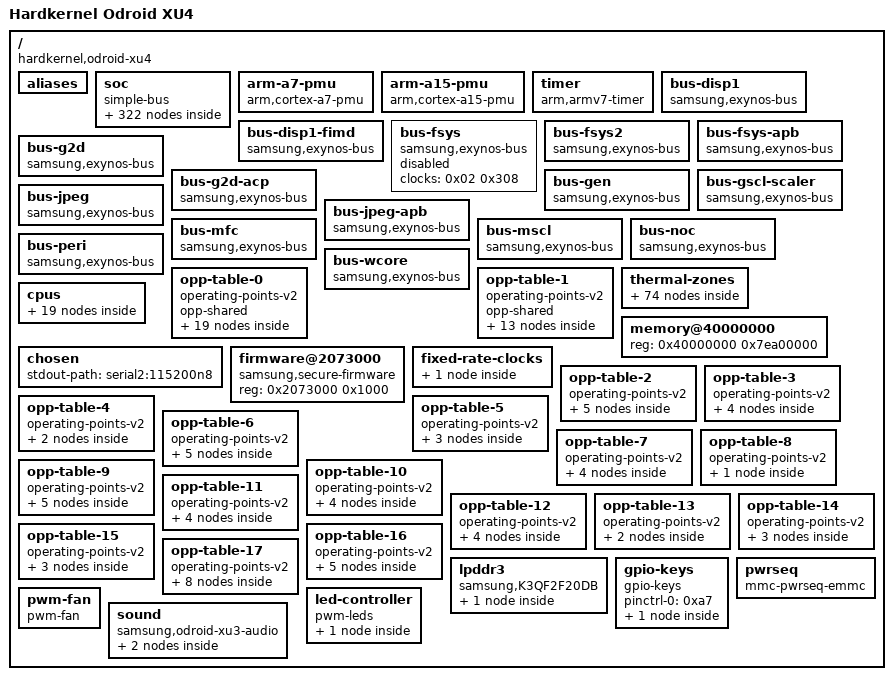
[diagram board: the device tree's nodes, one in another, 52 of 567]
/*
 * Copyright Linux Kernel Team
 *
 * SPDX-License-Identifier: GPL-2.0-only
 *
 * This file is derived from an intermediate build stage of the
 * Linux kernel. The licenses of all input files to this process
 * are compatible with GPL-2.0-only.
 */

/dts-v1/;

/ {
	interrupt-parent = <0x01>;
	#address-cells = <0x01>;
	#size-cells = <0x01>;
	compatible = "hardkernel,odroid-xu4", "samsung,exynos5800", "samsung,exynos5";
	model = "Hardkernel Odroid XU4";

	aliases {
		i2c0 = "/soc/i2c@12c60000";
		i2c1 = "/soc/i2c@12c70000";
		i2c2 = "/soc/i2c@12c80000";
		i2c3 = "/soc/i2c@12c90000";
		serial0 = "/soc/serial@12c00000";
		serial1 = "/soc/serial@12c10000";
		serial2 = "/soc/serial@12c20000";
		serial3 = "/soc/serial@12c30000";
		i2c4 = "/soc/i2c@12ca0000";
		i2c5 = "/soc/i2c@12cb0000";
		i2c6 = "/soc/i2c@12cc0000";
		i2c7 = "/soc/i2c@12cd0000";
		usbdrdphy0 = "/soc/phy@12100000";
		usbdrdphy1 = "/soc/phy@12500000";
		pinctrl0 = "/soc/pinctrl@13400000";
		pinctrl1 = "/soc/pinctrl@13410000";
		pinctrl2 = "/soc/pinctrl@14000000";
		pinctrl3 = "/soc/pinctrl@14010000";
		pinctrl4 = "/soc/pinctrl@3860000";
		i2c8 = "/soc/i2c@12e00000";
		i2c9 = "/soc/i2c@12e10000";
		i2c10 = "/soc/i2c@12e20000";
		gsc0 = "/soc/video-scaler@13e00000";
		gsc1 = "/soc/video-scaler@13e10000";
		spi0 = "/soc/spi@12d20000";
		spi1 = "/soc/spi@12d30000";
		spi2 = "/soc/spi@12d40000";
		mmc2 = "/soc/mmc@12220000";
		mmc0 = "/soc/mmc@12200000";
	};

	soc {
		compatible = "simple-bus";
		#address-cells = <0x01>;
		#size-cells = <0x01>;
		ranges;

		chipid@10000000 {
			compatible = "samsung,exynos4210-chipid";
			reg = <0x10000000 0x100>;
		};

		memory-controller@12250000 {
			compatible = "samsung,exynos4210-srom";
			reg = <0x12250000 0x14>;
		};

		interrupt-controller@10440000 {
			compatible = "samsung,exynos4210-combiner";
			#interrupt-cells = <0x02>;
			interrupt-controller;
			samsung,combiner-nr = <0x20>;
			reg = <0x10440000 0x1000>;
			interrupts = <0x00 0x00 0x04 0x00 0x01 0x04 0x00 0x02 0x04 0x00 0x03 0x04 0x00 0x04 0x04 0x00 0x05 0x04 0x00 0x06 0x04 0x00 0x07 0x04 0x00 0x08 0x04 0x00 0x09 0x04 0x00 0x0a 0x04 0x00 0x0b 0x04 0x00 0x0c 0x04 0x00 0x0d 0x04 0x00 0x0e 0x04 0x00 0x0f 0x04 0x00 0x10 0x04 0x00 0x11 0x04 0x00 0x12 0x04 0x00 0x13 0x04 0x00 0x14 0x04 0x00 0x15 0x04 0x00 0x16 0x04 0x00 0x17 0x04 0x00 0x18 0x04 0x00 0x19 0x04 0x00 0x1a 0x04 0x00 0x1b 0x04 0x00 0x1c 0x04 0x00 0x1d 0x04 0x00 0x1e 0x04 0x00 0x1f 0x04>;
			phandle = <0x0e>;
		};

		interrupt-controller@10481000 {
			compatible = "arm,gic-400", "arm,cortex-a15-gic";
			#interrupt-cells = <0x03>;
			interrupt-controller;
			reg = <0x10481000 0x1000 0x10482000 0x2000 0x10484000 0x2000 0x10486000 0x2000>;
			interrupts = <0x01 0x09 0xf04>;
			phandle = <0x01>;
		};

		syscon@10050000 {
			compatible = "samsung,exynos5-sysreg", "syscon";
			reg = <0x10050000 0x5000>;
			phandle = <0x05>;
		};

		serial@12c00000 {
			compatible = "samsung,exynos4210-uart";
			reg = <0x12c00000 0x100>;
			interrupts = <0x00 0x33 0x04>;
			clocks = <0x02 0x101 0x02 0x80>;
			clock-names = "uart", "clk_uart_baud0";
			dmas = <0x03 0x0d 0x03 0x0e>;
			dma-names = "rx", "tx";
		};

		serial@12c10000 {
			compatible = "samsung,exynos4210-uart";
			reg = <0x12c10000 0x100>;
			interrupts = <0x00 0x34 0x04>;
			clocks = <0x02 0x102 0x02 0x81>;
			clock-names = "uart", "clk_uart_baud0";
			dmas = <0x04 0x0f 0x04 0x10>;
			dma-names = "rx", "tx";
		};

		serial@12c20000 {
			compatible = "samsung,exynos4210-uart";
			reg = <0x12c20000 0x100>;
			interrupts = <0x00 0x35 0x04>;
			clocks = <0x02 0x103 0x02 0x82>;
			clock-names = "uart", "clk_uart_baud0";
			dmas = <0x03 0x0f 0x03 0x10>;
			dma-names = "rx", "tx";
		};

		serial@12c30000 {
			compatible = "samsung,exynos4210-uart";
			reg = <0x12c30000 0x100>;
			interrupts = <0x00 0x36 0x04>;
			clocks = <0x02 0x104 0x02 0x83>;
			clock-names = "uart", "clk_uart_baud0";
			dmas = <0x04 0x11 0x04 0x12>;
			dma-names = "rx", "tx";
		};

		i2c@12c60000 {
			compatible = "samsung,s3c2440-i2c";
			reg = <0x12c60000 0x100>;
			interrupts = <0x00 0x38 0x04>;
			#address-cells = <0x01>;
			#size-cells = <0x00>;
			samsung,sysreg-phandle = <0x05>;
			status = "disabled";
			clocks = <0x02 0x105>;
			clock-names = "i2c";
			pinctrl-names = "default";
			pinctrl-0 = <0x06>;
		};

		i2c@12c70000 {
			compatible = "samsung,s3c2440-i2c";
			reg = <0x12c70000 0x100>;
			interrupts = <0x00 0x39 0x04>;
			#address-cells = <0x01>;
			#size-cells = <0x00>;
			samsung,sysreg-phandle = <0x05>;
			status = "disabled";
			clocks = <0x02 0x106>;
			clock-names = "i2c";
			pinctrl-names = "default";
			pinctrl-0 = <0x07>;
		};

		i2c@12c80000 {
			compatible = "samsung,s3c2440-i2c";
			reg = <0x12c80000 0x100>;
			interrupts = <0x00 0x3a 0x04>;
			#address-cells = <0x01>;
			#size-cells = <0x00>;
			samsung,sysreg-phandle = <0x05>;
			status = "okay";
			clocks = <0x02 0x107>;
			clock-names = "i2c";
			pinctrl-names = "default";
			pinctrl-0 = <0x08>;
			samsung,i2c-sda-delay = <0x64>;
			samsung,i2c-max-bus-freq = <0x101d0>;
			phandle = <0x4e>;
		};

		i2c@12c90000 {
			compatible = "samsung,s3c2440-i2c";
			reg = <0x12c90000 0x100>;
			interrupts = <0x00 0x3b 0x04>;
			#address-cells = <0x01>;
			#size-cells = <0x00>;
			samsung,sysreg-phandle = <0x05>;
			status = "disabled";
			clocks = <0x02 0x108>;
			clock-names = "i2c";
			pinctrl-names = "default";
			pinctrl-0 = <0x09>;
		};

		pwm@12dd0000 {
			compatible = "samsung,exynos4210-pwm";
			reg = <0x12dd0000 0x100>;
			interrupts = <0x00 0x24 0x04 0x00 0x25 0x04 0x00 0x26 0x04 0x00 0x27 0x04 0x00 0x28 0x04>;
			samsung,pwm-outputs = <0x00 0x02>;
			#pwm-cells = <0x03>;
			clocks = <0x02 0x117>;
			clock-names = "timers";
			pinctrl-0 = <0x0a 0x0b>;
			pinctrl-names = "default";
			status = "okay";
			phandle = <0xaa>;
		};

		rtc@101e0000 {
			compatible = "samsung,s3c6410-rtc";
			reg = <0x101e0000 0x100>;
			interrupts = <0x00 0x2b 0x04 0x00 0x2c 0x04>;
			status = "okay";
			clocks = <0x02 0x13d 0x0c 0x00>;
			clock-names = "rtc", "rtc_src";
			interrupt-parent = <0x0d>;
		};

		fimd@14400000 {
			compatible = "samsung,exynos5420-fimd";
			interrupt-parent = <0x0e>;
			reg = <0x14400000 0x40000>;
			interrupt-names = "fifo", "vsync", "lcd_sys";
			interrupts = <0x12 0x04 0x12 0x05 0x12 0x06>;
			samsung,sysreg = <0x05>;
			status = "disabled";
			clocks = <0x02 0x93 0x02 0x1a5>;
			clock-names = "sclk_fimd", "fimd";
			power-domains = <0x0f>;
			iommus = <0x10 0x11>;
			iommu-names = "m0", "m1";
		};

		dp-controller@145b0000 {
			compatible = "samsung,exynos5-dp";
			reg = <0x145b0000 0x1000>;
			interrupts = <0x0a 0x03>;
			interrupt-parent = <0x0e>;
			status = "disabled";
			clocks = <0x02 0x19c>;
			clock-names = "dp";
			phys = <0x12>;
			phy-names = "dp";
			power-domains = <0x0f>;
		};

		sss@10830000 {
			compatible = "samsung,exynos4210-secss";
			reg = <0x10830000 0x300>;
			interrupts = <0x00 0x70 0x04>;
			clocks = <0x02 0x1d7>;
			clock-names = "secss";
		};

		rng@10830400 {
			compatible = "samsung,exynos5250-prng";
			reg = <0x10830400 0x200>;
			clocks = <0x02 0x1d7>;
			clock-names = "secss";
		};

		rng@10830600 {
			compatible = "samsung,exynos5250-trng";
			reg = <0x10830600 0x100>;
			clocks = <0x02 0x1d7>;
			clock-names = "secss";
		};

		g2d@10850000 {
			compatible = "samsung,exynos5250-g2d";
			reg = <0x10850000 0x1000>;
			interrupts = <0x00 0x5b 0x04>;
			status = "okay";
			iommus = <0x13 0x14>;
			clocks = <0x02 0x1e1>;
			clock-names = "fimg2d";
		};

		sram@2020000 {
			compatible = "mmio-sram";
			reg = <0x2020000 0x54000>;
			#address-cells = <0x01>;
			#size-cells = <0x01>;
			ranges = <0x00 0x2020000 0x54000>;

			smp-sram@0 {
				compatible = "samsung,exynos4210-sysram";
				reg = <0x00 0x1000>;
			};

			smp-sram@53000 {
				compatible = "samsung,exynos4210-sysram-ns";
				reg = <0x53000 0x1000>;
			};
		};

		timer@101c0000 {
			compatible = "samsung,exynos5420-mct", "samsung,exynos4210-mct";
			reg = <0x101c0000 0xb00>;
			interrupts-extended = <0x0e 0x17 0x03 0x0e 0x17 0x04 0x0e 0x19 0x02 0x0e 0x19 0x03 0x01 0x00 0x78 0x04 0x01 0x00 0x79 0x04 0x01 0x00 0x7a 0x04 0x01 0x00 0x7b 0x04 0x01 0x00 0x80 0x04 0x01 0x00 0x81 0x04 0x01 0x00 0x82 0x04 0x01 0x00 0x83 0x04>;
			clocks = <0x02 0x01 0x02 0x13b>;
			clock-names = "fin_pll", "mct";
		};

		watchdog@101d0000 {
			compatible = "samsung,exynos5420-wdt";
			reg = <0x101d0000 0x100>;
			interrupts = <0x00 0x2a 0x04>;
			clocks = <0x02 0x13c>;
			clock-names = "watchdog";
			samsung,syscon-phandle = <0x0d>;
		};

		adc@12d10000 {
			compatible = "samsung,exynos-adc-v2";
			reg = <0x12d10000 0x100>;
			interrupts = <0x00 0x6a 0x04>;
			#io-channel-cells = <0x01>;
			status = "okay";
			clocks = <0x02 0x10e>;
			clock-names = "adc";
			samsung,syscon-phandle = <0x0d>;
			vdd-supply = <0x15>;
		};

		i2c@12ca0000 {
			compatible = "samsung,exynos5250-hsi2c";
			reg = <0x12ca0000 0x1000>;
			interrupts = <0x00 0x3c 0x04>;
			#address-cells = <0x01>;
			#size-cells = <0x00>;
			status = "okay";
			clocks = <0x02 0x109>;
			clock-names = "hsi2c";
			pinctrl-names = "default";
			pinctrl-0 = <0x16>;

			pmic@66 {
				compatible = "samsung,s2mps11-pmic";
				reg = <0x66>;
				samsung,s2mps11-acokb-ground;
				interrupt-parent = <0x17>;
				interrupts = <0x04 0x08>;
				pinctrl-names = "default";
				pinctrl-0 = <0x18>;
				wakeup-source;

				clocks {
					compatible = "samsung,s2mps11-clk";
					#clock-cells = <0x01>;
					clock-output-names = "s2mps11_ap", "s2mps11_cp", "s2mps11_bt";
					phandle = <0x0c>;
				};

				regulators {

					LDO1 {
						regulator-name = "vdd_ldo1";
						regulator-min-microvolt = <0xf4240>;
						regulator-max-microvolt = <0xf4240>;
						regulator-always-on;
					};

					LDO2 {
						regulator-name = "vdd_ldo2";
						regulator-min-microvolt = <0x1b7740>;
						regulator-max-microvolt = <0x1b7740>;
						regulator-always-on;
					};

					LDO3 {
						regulator-name = "vddq_mmc0";
						regulator-min-microvolt = <0x1b7740>;
						regulator-max-microvolt = <0x1b7740>;
						phandle = <0x30>;
					};

					LDO4 {
						regulator-name = "vdd_adc";
						regulator-min-microvolt = <0x1b7740>;
						regulator-max-microvolt = <0x1b7740>;
						phandle = <0x15>;

						regulator-state-mem {
							regulator-off-in-suspend;
						};
					};

					LDO5 {
						regulator-name = "vdd_ldo5";
						regulator-min-microvolt = <0x1b7740>;
						regulator-max-microvolt = <0x1b7740>;
						regulator-always-on;

						regulator-state-mem {
							regulator-off-in-suspend;
						};
					};

					LDO6 {
						regulator-name = "vdd_ldo6";
						regulator-min-microvolt = <0xf4240>;
						regulator-max-microvolt = <0xf4240>;
						regulator-always-on;
						phandle = <0x52>;

						regulator-state-mem {
							regulator-off-in-suspend;
						};
					};

					LDO7 {
						regulator-name = "vdd_ldo7";
						regulator-min-microvolt = <0x1b7740>;
						regulator-max-microvolt = <0x1b7740>;
						regulator-always-on;
						phandle = <0x51>;

						regulator-state-mem {
							regulator-off-in-suspend;
						};
					};

					LDO8 {
						regulator-name = "vdd_ldo8";
						regulator-min-microvolt = <0x1b7740>;
						regulator-max-microvolt = <0x1b7740>;
						regulator-always-on;

						regulator-state-mem {
							regulator-off-in-suspend;
						};
					};

					LDO9 {
						regulator-name = "vdd_ldo9";
						regulator-min-microvolt = <0x2dc6c0>;
						regulator-max-microvolt = <0x2dc6c0>;
						regulator-always-on;
						phandle = <0x1e>;

						regulator-state-mem {
							regulator-off-in-suspend;
						};
					};

					LDO10 {
						regulator-name = "vdd_ldo10";
						regulator-min-microvolt = <0x1b7740>;
						regulator-max-microvolt = <0x1b7740>;
						regulator-always-on;

						regulator-state-mem {
							regulator-off-in-suspend;
						};
					};

					LDO11 {
						regulator-name = "vdd_ldo11";
						regulator-min-microvolt = <0xf4240>;
						regulator-max-microvolt = <0xf4240>;
						regulator-always-on;
						phandle = <0x1f>;

						regulator-state-mem {
							regulator-off-in-suspend;
						};
					};

					LDO12 {
						regulator-name = "vdd_ldo12";
						regulator-min-microvolt = "", "\f5";
						regulator-max-microvolt = <0x243d58>;
					};

					LDO13 {
						regulator-name = "vddq_mmc2";
						regulator-min-microvolt = <0x1b7740>;
						regulator-max-microvolt = <0x2ab980>;
						phandle = <0x38>;

						regulator-state-mem {
							regulator-off-in-suspend;
						};
					};

					LDO14 {
						regulator-name = "vdd_ldo14";
						regulator-min-microvolt = "", "\f5";
						regulator-max-microvolt = <0x3c45b0>;
					};

					LDO15 {
						regulator-name = "vdd_ldo15";
						regulator-min-microvolt = <0x325aa0>;
						regulator-max-microvolt = <0x325aa0>;
						regulator-always-on;

						regulator-state-mem {
							regulator-off-in-suspend;
						};
					};

					LDO16 {
						regulator-name = "vdd_ldo16";
						regulator-min-microvolt = "", "\f5";
						regulator-max-microvolt = <0x3c45b0>;
					};

					LDO17 {
						regulator-name = "vdd_ldo17";
						regulator-min-microvolt = <0x325aa0>;
						regulator-max-microvolt = <0x325aa0>;
						regulator-always-on;

						regulator-state-mem {
							regulator-off-in-suspend;
						};
					};

					LDO18 {
						regulator-name = "vdd_emmc_1V8";
						regulator-min-microvolt = <0x1b7740>;
						regulator-max-microvolt = <0x1b7740>;
						phandle = <0x2f>;

						regulator-state-mem {
							regulator-off-in-suspend;
						};
					};

					LDO19 {
						regulator-name = "vdd_sd";
						regulator-min-microvolt = <0x2ab980>;
						regulator-max-microvolt = <0x2ab980>;
						phandle = <0x37>;

						regulator-state-mem {
							regulator-off-in-suspend;
						};
					};

					LDO20 {
						regulator-name = "vdd_ldo20";
						regulator-min-microvolt = "", "\f5";
						regulator-max-microvolt = <0x3c45b0>;
					};

					LDO21 {
						regulator-name = "vdd_ldo21";
						regulator-min-microvolt = "", "\f5";
						regulator-max-microvolt = <0x3c45b0>;
					};

					LDO22 {
						regulator-name = "vdd_ldo22";
						regulator-min-microvolt = "", "\f5";
						regulator-max-microvolt = <0x243d58>;
					};

					LDO23 {
						regulator-name = "vdd_mifs";
						regulator-min-microvolt = <0x10c8e0>;
						regulator-max-microvolt = <0x10c8e0>;
						regulator-always-on;

						regulator-state-mem {
							regulator-off-in-suspend;
						};
					};

					LDO24 {
						regulator-name = "vdd_ldo24";
						regulator-min-microvolt = "", "\f5";
						regulator-max-microvolt = <0x3c45b0>;
					};

					LDO25 {
						regulator-name = "vdd_ldo25";
						regulator-min-microvolt = "", "\f5";
						regulator-max-microvolt = <0x3c45b0>;
					};

					LDO26 {
						regulator-name = "vdd_ldo26";
						regulator-min-microvolt = <0x2dc6c0>;
						regulator-max-microvolt = <0x2dc6c0>;
						regulator-always-on;

						regulator-state-mem {
							regulator-off-in-suspend;
						};
					};

					LDO27 {
						regulator-name = "vdd_g3ds";
						regulator-min-microvolt = <0xf4240>;
						regulator-max-microvolt = <0xf4240>;
						regulator-always-on;

						regulator-state-mem {
							regulator-off-in-suspend;
						};
					};

					LDO28 {
						regulator-name = "vdd_ldo28";
						regulator-min-microvolt = "", "\f5";
						regulator-max-microvolt = <0x3c45b0>;

						regulator-state-mem {
							regulator-off-in-suspend;
						};
					};

					LDO29 {
						regulator-name = "vdd_ldo29";
						regulator-min-microvolt = "", "\f5";
						regulator-max-microvolt = <0x3c45b0>;
					};

					LDO30 {
						regulator-name = "vdd_ldo30";
						regulator-min-microvolt = "", "\f5";
						regulator-max-microvolt = <0x3c45b0>;
					};

					LDO31 {
						regulator-name = "vdd_ldo31";
						regulator-min-microvolt = "", "\f5";
						regulator-max-microvolt = <0x3c45b0>;
					};

					LDO32 {
						regulator-name = "vdd_ldo32";
						regulator-min-microvolt = "", "\f5";
						regulator-max-microvolt = <0x3c45b0>;
					};

					LDO33 {
						regulator-name = "vdd_ldo33";
						regulator-min-microvolt = "", "\f5";
						regulator-max-microvolt = <0x3c45b0>;
					};

					LDO34 {
						regulator-name = "vdd_ldo34";
						regulator-min-microvolt = "", "\f5";
						regulator-max-microvolt = <0x3c45b0>;
					};

					LDO35 {
						regulator-name = "vdd_ldo35";
						regulator-min-microvolt = "", "\f5";
						regulator-max-microvolt = <0x243d58>;
					};

					LDO36 {
						regulator-name = "vdd_ldo36";
						regulator-min-microvolt = "", "\f5";
						regulator-max-microvolt = <0x3c45b0>;
					};

					LDO37 {
						regulator-name = "vdd_ldo37";
						regulator-min-microvolt = "", "\f5";
						regulator-max-microvolt = <0x3c45b0>;
					};

					LDO38 {
						regulator-name = "vdd_ldo38";
						regulator-min-microvolt = "", "\f5";
						regulator-max-microvolt = <0x3c45b0>;
					};

					BUCK1 {
						regulator-name = "vdd_mif";
						regulator-min-microvolt = "", "\f5";
						regulator-max-microvolt = <0x13d620>;
						regulator-always-on;
						regulator-boot-on;
						phandle = <0x3f>;

						regulator-state-mem {
							regulator-off-in-suspend;
						};
					};

					BUCK2 {
						regulator-name = "vdd_arm";
						regulator-min-microvolt = "", "\f5";
						regulator-max-microvolt = <0x16e360>;
						regulator-always-on;
						regulator-boot-on;
						regulator-coupled-with = <0x19>;
						regulator-coupled-max-spread = <0x493e0>;
						phandle = <0x1a>;

						regulator-state-mem {
							regulator-off-in-suspend;
						};
					};

					BUCK3 {
						regulator-name = "vdd_int";
						regulator-min-microvolt = "", "\f5";
						regulator-max-microvolt = <0x155cc0>;
						regulator-always-on;
						regulator-boot-on;
						regulator-coupled-with = <0x1a>;
						regulator-coupled-max-spread = <0x493e0>;
						phandle = <0x19>;

						regulator-state-mem {
							regulator-off-in-suspend;
						};
					};

					BUCK4 {
						regulator-name = "vdd_g3d";
						regulator-min-microvolt = "", "\f5";
						regulator-max-microvolt = <0x155cc0>;
						regulator-boot-on;
						regulator-always-on;
						phandle = <0x5c>;

						regulator-state-mem {
							regulator-off-in-suspend;
						};
					};

					BUCK5 {
						regulator-name = "vdd_mem";
						regulator-min-microvolt = "", "\f5";
						regulator-max-microvolt = <0x155cc0>;
						regulator-always-on;
						regulator-boot-on;
					};

					BUCK6 {
						regulator-name = "vdd_kfc";
						regulator-min-microvolt = "", "\f5";
						regulator-max-microvolt = <0x16e360>;
						regulator-always-on;
						regulator-boot-on;
						phandle = <0xa4>;

						regulator-state-mem {
							regulator-off-in-suspend;
						};
					};

					BUCK7 {
						regulator-name = "vdd_1.35v_ldo";
						regulator-min-microvolt = <0x124f80>;
						regulator-max-microvolt = <0x16e360>;
						regulator-always-on;
						regulator-boot-on;
					};

					BUCK8 {
						regulator-name = "vdd_2.0v_ldo";
						regulator-min-microvolt = <0x1b7740>;
						regulator-max-microvolt = <0x200b20>;
						regulator-always-on;
						regulator-boot-on;
					};

					BUCK9 {
						regulator-name = "vdd_2.8v_ldo";
						regulator-min-microvolt = <0x2dc6c0>;
						regulator-max-microvolt = <0x393870>;
						regulator-always-on;
						regulator-boot-on;

						regulator-state-mem {
							regulator-off-in-suspend;
						};
					};

					BUCK10 {
						regulator-name = "vdd_vmem";
						regulator-min-microvolt = <0x2b7cd0>;
						regulator-max-microvolt = <0x2b7cd0>;
						regulator-always-on;
						regulator-boot-on;

						regulator-state-mem {
							regulator-off-in-suspend;
						};
					};
				};
			};
		};

		i2c@12cb0000 {
			compatible = "samsung,exynos5250-hsi2c";
			reg = <0x12cb0000 0x1000>;
			interrupts = <0x00 0x3d 0x04>;
			#address-cells = <0x01>;
			#size-cells = <0x00>;
			status = "disabled";
			clocks = <0x02 0x10a>;
			clock-names = "hsi2c";
			pinctrl-names = "default";
			pinctrl-0 = <0x1b>;
		};

		i2c@12cc0000 {
			compatible = "samsung,exynos5250-hsi2c";
			reg = <0x12cc0000 0x1000>;
			interrupts = <0x00 0x3e 0x04>;
			#address-cells = <0x01>;
			#size-cells = <0x00>;
			status = "disabled";
			clocks = <0x02 0x10b>;
			clock-names = "hsi2c";
			pinctrl-names = "default";
			pinctrl-0 = <0x1c>;
		};

		i2c@12cd0000 {
			compatible = "samsung,exynos5250-hsi2c";
			reg = <0x12cd0000 0x1000>;
			interrupts = <0x00 0x3f 0x04>;
			#address-cells = <0x01>;
			#size-cells = <0x00>;
			status = "disabled";
			clocks = <0x02 0x10c>;
			clock-names = "hsi2c";
			pinctrl-names = "default";
			pinctrl-0 = <0x1d>;
		};

		usb@12000000 {
			compatible = "samsung,exynos5250-dwusb3";
			#address-cells = <0x01>;
			#size-cells = <0x01>;
			ranges = <0x00 0x12000000 0x10000>;
			clocks = <0x02 0x16e>;
			clock-names = "usbdrd30";
			vdd33-supply = <0x1e>;
			vdd10-supply = <0x1f>;

			usb@0 {
				compatible = "snps,dwc3";
				reg = <0x00 0x10000>;
				interrupts = <0x00 0x48 0x04>;
				phys = <0x20 0x00 0x20 0x01>;
				phy-names = "usb2-phy", "usb3-phy";
				snps,dis_u3_susphy_quirk;
				dr_mode = "host";
			};
		};

		phy@12100000 {
			compatible = "samsung,exynos5420-usbdrd-phy";
			reg = <0x12100000 0x100>;
			#phy-cells = <0x01>;
			clocks = <0x02 0x16e 0x02 0x98>;
			clock-names = "phy", "ref";
			samsung,pmu-syscon = <0x0d>;
			phandle = <0x20>;
		};

		usb@12400000 {
			compatible = "samsung,exynos5250-dwusb3";
			#address-cells = <0x01>;
			#size-cells = <0x01>;
			ranges = <0x00 0x12400000 0x10000>;
			clocks = <0x02 0x16f>;
			clock-names = "usbdrd30";
			vdd33-supply = <0x1e>;
			vdd10-supply = <0x1f>;

			usb@0 {
				compatible = "snps,dwc3";
				reg = <0x00 0x10000>;
				phys = <0x21 0x00 0x21 0x01>;
				phy-names = "usb2-phy", "usb3-phy";
				snps,dis_u3_susphy_quirk;
				interrupts = <0x00 0x49 0x04>;
				dr_mode = "host";
			};
		};

		phy@12500000 {
			compatible = "samsung,exynos5420-usbdrd-phy";
			reg = <0x12500000 0x100>;
			#phy-cells = <0x01>;
			clocks = <0x02 0x16f 0x02 0x99>;
			clock-names = "phy", "ref";
			samsung,pmu-syscon = <0x0d>;
			phandle = <0x21>;
		};

		usb@12110000 {
			compatible = "samsung,exynos4210-ehci";
			reg = <0x12110000 0x100>;
			interrupts = <0x00 0x47 0x04>;
			phys = <0x22 0x00>;
			phy-names = "host";
			clocks = <0x02 0x16d>;
			clock-names = "usbhost";
		};

		usb@12120000 {
			compatible = "samsung,exynos4210-ohci";
			reg = <0x12120000 0x100>;
			interrupts = <0x00 0x47 0x04>;
			phys = <0x22 0x00>;
			phy-names = "host";
			clocks = <0x02 0x16d>;
			clock-names = "usbhost";
		};

		phy@12130000 {
			compatible = "samsung,exynos5420-usb2-phy";
			reg = <0x12130000 0x100>;
			#phy-cells = <0x01>;
			clocks = <0x02 0x16d 0x02 0x98>;
			clock-names = "phy", "ref";
			samsung,sysreg-phandle = <0x05>;
			samsung,pmureg-phandle = <0x0d>;
			phandle = <0x22>;
		};

		cci@10d20000 {
			compatible = "arm,cci-400";
			#address-cells = <0x01>;
			#size-cells = <0x01>;
			reg = <0x10d20000 0x1000>;
			ranges = <0x00 0x10d20000 0x6000>;

			slave-if@4000 {
				compatible = "arm,cci-400-ctrl-if";
				interface-type = "ace";
				reg = <0x4000 0x1000>;
				phandle = <0xa2>;
			};

			slave-if@5000 {
				compatible = "arm,cci-400-ctrl-if";
				interface-type = "ace";
				reg = <0x5000 0x1000>;
				phandle = <0xa5>;
			};
		};

		clock-controller@10010000 {
			compatible = "samsung,exynos5800-clock", "syscon";
			reg = <0x10010000 0x30000>;
			#clock-cells = <0x01>;
			phandle = <0x02>;
		};

		audss-clock-controller@3810000 {
			compatible = "samsung,exynos5420-audss-clock";
			reg = <0x3810000 0x0c>;
			#clock-cells = <0x01>;
			clocks = <0x02 0x01 0x02 0x9f 0x02 0x94 0x02 0x95>;
			clock-names = "pll_ref", "pll_in", "sclk_audio", "sclk_pcm_in";
			power-domains = <0x23>;
			phandle = <0x40>;
		};

		codec@11000000 {
			compatible = "samsung,mfc-v8";
			reg = <0x11000000 0x10000>;
			interrupts = <0x00 0x60 0x04>;
			clocks = <0x02 0x191>;
			clock-names = "mfc";
			power-domains = <0x24>;
			iommus = <0x25 0x26>;
			iommu-names = "left", "right";
		};

		mmc@12200000 {
			compatible = "samsung,exynos5420-dw-mshc-smu";
			interrupts = <0x00 0x4b 0x04>;
			#address-cells = <0x01>;
			#size-cells = <0x00>;
			reg = <0x12200000 0x2000>;
			clocks = <0x02 0x15f 0x02 0x84>;
			clock-names = "biu", "ciu";
			fifo-depth = <0x40>;
			status = "okay";
			mmc-pwrseq = <0x27>;
			card-detect-delay = <0xc8>;
			samsung,dw-mshc-ciu-div = <0x03>;
			samsung,dw-mshc-sdr-timing = <0x00 0x04>;
			samsung,dw-mshc-ddr-timing = <0x00 0x02>;
			samsung,dw-mshc-hs400-timing = <0x00 0x02>;
			samsung,read-strobe-delay = <0x5a>;
			pinctrl-names = "default";
			pinctrl-0 = <0x28 0x29 0x2a 0x2b 0x2c 0x2d 0x2e>;
			bus-width = <0x08>;
			cap-mmc-highspeed;
			mmc-ddr-1_8v;
			mmc-hs200-1_8v;
			mmc-hs400-1_8v;
			max-frequency = <0xbebc200>;
			vmmc-supply = <0x2f>;
			vqmmc-supply = <0x30>;
		};

		mmc@12210000 {
			compatible = "samsung,exynos5420-dw-mshc-smu";
			interrupts = <0x00 0x4c 0x04>;
			#address-cells = <0x01>;
			#size-cells = <0x00>;
			reg = <0x12210000 0x2000>;
			clocks = <0x02 0x160 0x02 0x85>;
			clock-names = "biu", "ciu";
			fifo-depth = <0x40>;
			status = "disabled";
		};

		mmc@12220000 {
			compatible = "samsung,exynos5420-dw-mshc";
			interrupts = <0x00 0x4d 0x04>;
			#address-cells = <0x01>;
			#size-cells = <0x00>;
			reg = <0x12220000 0x1000>;
			clocks = <0x02 0x161 0x02 0x86>;
			clock-names = "biu", "ciu";
			fifo-depth = <0x40>;
			status = "okay";
			card-detect-delay = <0xc8>;
			samsung,dw-mshc-ciu-div = <0x03>;
			samsung,dw-mshc-sdr-timing = <0x00 0x04>;
			samsung,dw-mshc-ddr-timing = <0x00 0x02>;
			pinctrl-names = "default";
			pinctrl-0 = <0x31 0x32 0x33 0x34 0x35 0x36>;
			bus-width = <0x04>;
			cap-sd-highspeed;
			max-frequency = <0xbebc200>;
			vmmc-supply = <0x37>;
			vqmmc-supply = <0x38>;
			sd-uhs-sdr50;
			sd-uhs-sdr104;
			sd-uhs-ddr50;
		};

		memory-controller@10c20000 {
			compatible = "samsung,exynos5422-dmc";
			reg = <0x10c20000 0x10000 0x10c30000 0x10000>;
			clocks = <0x02 0x08 0x02 0x294 0x02 0x31d 0x02 0x0b 0x02 0x28f 0x02 0xa2 0x02 0x290 0x02 0x28e>;
			clock-names = "fout_spll", "mout_sclk_spll", "ff_dout_spll2", "fout_bpll", "mout_bpll", "sclk_bpll", "mout_mx_mspll_ccore", "mout_mclk_cdrex";
			samsung,syscon-clk = <0x02>;
			status = "okay";
			devfreq-events = <0x39 0x3a 0x3b 0x3c>;
			device-handle = <0x3d>;
			operating-points-v2 = <0x3e>;
			vdd-supply = <0x3f>;
		};

		nocp@10ca1000 {
			compatible = "samsung,exynos5420-nocp";
			reg = <0x10ca1000 0x200>;
			status = "okay";
			phandle = <0x7e>;
		};

		nocp@10ca1400 {
			compatible = "samsung,exynos5420-nocp";
			reg = <0x10ca1400 0x200>;
			status = "okay";
			phandle = <0x7f>;
		};

		nocp@10ca1800 {
			compatible = "samsung,exynos5420-nocp";
			reg = <0x10ca1800 0x200>;
			status = "okay";
			phandle = <0x80>;
		};

		nocp@10ca1c00 {
			compatible = "samsung,exynos5420-nocp";
			reg = <0x10ca1c00 0x200>;
			status = "okay";
			phandle = <0x81>;
		};

		nocp@11a51000 {
			compatible = "samsung,exynos5420-nocp";
			reg = <0x11a51000 0x200>;
			status = "disabled";
		};

		nocp@11a51400 {
			compatible = "samsung,exynos5420-nocp";
			reg = <0x11a51400 0x200>;
			status = "disabled";
		};

		ppmu@10d00000 {
			compatible = "samsung,exynos-ppmu";
			reg = <0x10d00000 0x2000>;
			clocks = <0x02 0x20f>;
			clock-names = "ppmu";
			status = "okay";

			events {

				ppmu-event3-dmc0-0 {
					event-name = "ppmu-event3-dmc0-0";
					phandle = <0x39>;
				};
			};
		};

		ppmu@10d10000 {
			compatible = "samsung,exynos-ppmu";
			reg = <0x10d10000 0x2000>;
			clocks = <0x02 0x210>;
			clock-names = "ppmu";
			status = "okay";

			events {

				ppmu-event3-dmc0-1 {
					event-name = "ppmu-event3-dmc0-1";
					phandle = <0x3a>;
				};
			};
		};

		ppmu@10d60000 {
			compatible = "samsung,exynos-ppmu";
			reg = <0x10d60000 0x2000>;
			clocks = <0x02 0x211>;
			clock-names = "ppmu";
			status = "okay";

			events {

				ppmu-event3-dmc1-0 {
					event-name = "ppmu-event3-dmc1-0";
					phandle = <0x3b>;
				};
			};
		};

		ppmu@10d70000 {
			compatible = "samsung,exynos-ppmu";
			reg = <0x10d70000 0x2000>;
			clocks = <0x02 0x212>;
			clock-names = "ppmu";
			status = "okay";

			events {

				ppmu-event3-dmc1-1 {
					event-name = "ppmu-event3-dmc1-1";
					phandle = <0x3c>;
				};
			};
		};

		power-domain@10044000 {
			compatible = "samsung,exynos4210-pd";
			reg = <0x10044000 0x20>;
			#power-domain-cells = <0x00>;
			label = "GSC";
			phandle = <0x57>;
		};

		power-domain@10044020 {
			compatible = "samsung,exynos4210-pd";
			reg = <0x10044020 0x20>;
			#power-domain-cells = <0x00>;
			label = "ISP";
		};

		power-domain@10044060 {
			compatible = "samsung,exynos4210-pd";
			reg = <0x10044060 0x20>;
			#power-domain-cells = <0x00>;
			label = "MFC";
			phandle = <0x24>;
		};

		power-domain@10044080 {
			compatible = "samsung,exynos4210-pd";
			reg = <0x10044080 0x20>;
			#power-domain-cells = <0x00>;
			label = "G3D";
			phandle = <0x5a>;
		};

		power-domain@100440c0 {
			compatible = "samsung,exynos4210-pd";
			reg = <0x100440c0 0x20>;
			#power-domain-cells = <0x00>;
			label = "DISP";
			phandle = <0x0f>;
		};

		power-domain@100440e0 {
			compatible = "samsung,exynos4210-pd";
			reg = <0x100440e0 0x20>;
			#power-domain-cells = <0x00>;
			label = "MAU";
			phandle = <0x23>;
		};

		power-domain@10044120 {
			compatible = "samsung,exynos4210-pd";
			reg = <0x10044120 0x20>;
			#power-domain-cells = <0x00>;
			label = "MSC";
			phandle = <0x5d>;
		};

		pinctrl@13400000 {
			compatible = "samsung,exynos5420-pinctrl";
			reg = <0x13400000 0x1000>;
			interrupts = <0x00 0x2d 0x04>;

			wakeup-interrupt-controller {
				compatible = "samsung,exynos4210-wakeup-eint";
				interrupt-parent = <0x01>;
				interrupts = <0x00 0x20 0x04>;
			};

			gpy7-gpio-bank {
				gpio-controller;
				#gpio-cells = <0x02>;
				interrupt-controller;
				#interrupt-cells = <0x02>;
			};

			gpx0-gpio-bank {
				gpio-controller;
				#gpio-cells = <0x02>;
				interrupt-controller;
				interrupt-parent = <0x0e>;
				#interrupt-cells = <0x02>;
				interrupts = <0x17 0x00 0x18 0x00 0x19 0x00 0x19 0x01 0x1a 0x00 0x1a 0x01 0x1b 0x00 0x1b 0x01>;
				phandle = <0x17>;
			};

			gpx1-gpio-bank {
				gpio-controller;
				#gpio-cells = <0x02>;
				interrupt-controller;
				interrupt-parent = <0x0e>;
				#interrupt-cells = <0x02>;
				interrupts = <0x1c 0x00 0x1c 0x01 0x1d 0x00 0x1d 0x01 0x1e 0x00 0x1e 0x01 0x1f 0x00 0x1f 0x01>;
			};

			gpx2-gpio-bank {
				gpio-controller;
				#gpio-cells = <0x02>;
				interrupt-controller;
				#interrupt-cells = <0x02>;
			};

			gpx3-gpio-bank {
				gpio-controller;
				#gpio-cells = <0x02>;
				interrupt-controller;
				#interrupt-cells = <0x02>;
				phandle = <0x4f>;
			};

			dp-hpd-pins {
				samsung,pins = "gpx0-7";
				samsung,pin-function = <0x03>;
				samsung,pin-pud = <0x00>;
				samsung,pin-drv = <0x00>;
			};

			hdmi-cec-pins {
				samsung,pins = "gpx3-6";
				samsung,pin-function = <0x03>;
				samsung,pin-pud = <0x00>;
				samsung,pin-drv = <0x00>;
				phandle = <0x54>;
			};

			s2mps11-irq-pins {
				samsung,pins = "gpx0-4";
				samsung,pin-function = <0x0f>;
				samsung,pin-pud = <0x00>;
				samsung,pin-drv = <0x00>;
				phandle = <0x18>;
			};

			power-key-pins {
				samsung,pins = "gpx0-3";
				samsung,pin-function = <0x00>;
				samsung,pin-pud = <0x00>;
				samsung,pin-drv = <0x00>;
				phandle = <0xa7>;
			};

			hdmi-hpd-irq-pins {
				samsung,pins = "gpx3-7";
				samsung,pin-function = <0x00>;
				samsung,pin-pud = <0x01>;
				samsung,pin-drv = <0x00>;
				phandle = <0x50>;
			};
		};

		pinctrl@13410000 {
			compatible = "samsung,exynos5420-pinctrl";
			reg = <0x13410000 0x1000>;
			interrupts = <0x00 0x4e 0x04>;

			gpc0-gpio-bank {
				gpio-controller;
				#gpio-cells = <0x02>;
				interrupt-controller;
				#interrupt-cells = <0x02>;
			};

			gpc1-gpio-bank {
				gpio-controller;
				#gpio-cells = <0x02>;
				interrupt-controller;
				#interrupt-cells = <0x02>;
			};

			gpc2-gpio-bank {
				gpio-controller;
				#gpio-cells = <0x02>;
				interrupt-controller;
				#interrupt-cells = <0x02>;
			};

			gpc3-gpio-bank {
				gpio-controller;
				#gpio-cells = <0x02>;
				interrupt-controller;
				#interrupt-cells = <0x02>;
			};

			gpc4-gpio-bank {
				gpio-controller;
				#gpio-cells = <0x02>;
				interrupt-controller;
				#interrupt-cells = <0x02>;
			};

			gpd1-gpio-bank {
				gpio-controller;
				#gpio-cells = <0x02>;
				interrupt-controller;
				#interrupt-cells = <0x02>;
				phandle = <0xa9>;
			};

			gpy0-gpio-bank {
				gpio-controller;
				#gpio-cells = <0x02>;
			};

			gpy1-gpio-bank {
				gpio-controller;
				#gpio-cells = <0x02>;
			};

			gpy2-gpio-bank {
				gpio-controller;
				#gpio-cells = <0x02>;
			};

			gpy3-gpio-bank {
				gpio-controller;
				#gpio-cells = <0x02>;
			};

			gpy4-gpio-bank {
				gpio-controller;
				#gpio-cells = <0x02>;
			};

			gpy5-gpio-bank {
				gpio-controller;
				#gpio-cells = <0x02>;
			};

			gpy6-gpio-bank {
				gpio-controller;
				#gpio-cells = <0x02>;
			};

			sd0-clk-pins {
				samsung,pins = "gpc0-0";
				samsung,pin-function = <0x02>;
				samsung,pin-pud = <0x00>;
				samsung,pin-drv = <0x03>;
				phandle = <0x28>;
			};

			sd0-cmd-pins {
				samsung,pins = "gpc0-1";
				samsung,pin-function = <0x02>;
				samsung,pin-pud = <0x00>;
				samsung,pin-drv = <0x03>;
				phandle = <0x29>;
			};

			sd0-cd-pins {
				samsung,pins = "gpc0-2";
				samsung,pin-function = <0x02>;
				samsung,pin-pud = <0x03>;
				samsung,pin-drv = <0x03>;
				phandle = <0x2d>;
			};

			sd0-bus-width1-pins {
				samsung,pins = "gpc0-3";
				samsung,pin-function = <0x02>;
				samsung,pin-pud = <0x03>;
				samsung,pin-drv = <0x03>;
				phandle = <0x2a>;
			};

			sd0-bus-width4-pins {
				samsung,pins = "gpc0-4", "gpc0-5", "gpc0-6";
				samsung,pin-function = <0x02>;
				samsung,pin-pud = <0x03>;
				samsung,pin-drv = <0x03>;
				phandle = <0x2b>;
			};

			sd0-bus-width8-pins {
				samsung,pins = "gpc3-0", "gpc3-1", "gpc3-2", "gpc3-3";
				samsung,pin-function = <0x02>;
				samsung,pin-pud = <0x03>;
				samsung,pin-drv = <0x03>;
				phandle = <0x2c>;
			};

			sd0-rclk-pins {
				samsung,pins = "gpc0-7";
				samsung,pin-function = <0x02>;
				samsung,pin-pud = <0x01>;
				samsung,pin-drv = <0x03>;
				phandle = <0x2e>;
			};

			sd1-clk-pins {
				samsung,pins = "gpc1-0";
				samsung,pin-function = <0x02>;
				samsung,pin-pud = <0x00>;
				samsung,pin-drv = <0x03>;
			};

			sd1-cmd-pins {
				samsung,pins = "gpc1-1";
				samsung,pin-function = <0x02>;
				samsung,pin-pud = <0x00>;
				samsung,pin-drv = <0x03>;
			};

			sd1-cd-pins {
				samsung,pins = "gpc1-2";
				samsung,pin-function = <0x02>;
				samsung,pin-pud = <0x03>;
				samsung,pin-drv = <0x03>;
			};

			sd1-int-pins {
				samsung,pins = "gpd1-1";
				samsung,pin-function = <0x02>;
				samsung,pin-pud = <0x03>;
				samsung,pin-drv = <0x00>;
			};

			sd1-bus-width1-pins {
				samsung,pins = "gpc1-3";
				samsung,pin-function = <0x02>;
				samsung,pin-pud = <0x03>;
				samsung,pin-drv = <0x03>;
			};

			sd1-bus-width4-pins {
				samsung,pins = "gpc1-4", "gpc1-5", "gpc1-6";
				samsung,pin-function = <0x02>;
				samsung,pin-pud = <0x03>;
				samsung,pin-drv = <0x03>;
			};

			sd1-bus-width8-pins {
				samsung,pins = "gpd1-4", "gpd1-5", "gpd1-6", "gpd1-7";
				samsung,pin-function = <0x02>;
				samsung,pin-pud = <0x03>;
				samsung,pin-drv = <0x03>;
			};

			sd2-clk-pins {
				samsung,pins = "gpc2-0";
				samsung,pin-function = <0x02>;
				samsung,pin-pud = <0x00>;
				samsung,pin-drv = <0x03>;
				phandle = <0x31>;
			};

			sd2-cmd-pins {
				samsung,pins = "gpc2-1";
				samsung,pin-function = <0x02>;
				samsung,pin-pud = <0x00>;
				samsung,pin-drv = <0x03>;
				phandle = <0x32>;
			};

			sd2-cd-pins {
				samsung,pins = "gpc2-2";
				samsung,pin-function = <0x02>;
				samsung,pin-pud = <0x03>;
				samsung,pin-drv = <0x03>;
				phandle = <0x33>;
			};

			sd2-bus-width1-pins {
				samsung,pins = "gpc2-3";
				samsung,pin-function = <0x02>;
				samsung,pin-pud = <0x03>;
				samsung,pin-drv = <0x03>;
				phandle = <0x35>;
			};

			sd2-bus-width4-pins {
				samsung,pins = "gpc2-4", "gpc2-5", "gpc2-6";
				samsung,pin-function = <0x02>;
				samsung,pin-pud = <0x03>;
				samsung,pin-drv = <0x03>;
				phandle = <0x36>;
			};

			sd2-wp-pins {
				samsung,pins = "gpc4-0";
				samsung,pin-function = <0x02>;
				samsung,pin-pud = <0x01>;
				samsung,pin-drv = <0x03>;
				phandle = <0x34>;
			};

			emmc-nrst-pins {
				samsung,pins = "gpd1-0";
				samsung,pin-function = <0x00>;
				samsung,pin-pud = <0x00>;
				samsung,pin-drv = <0x00>;
				phandle = <0xa8>;
			};
		};

		pinctrl@14000000 {
			compatible = "samsung,exynos5420-pinctrl";
			reg = <0x14000000 0x1000>;
			interrupts = <0x00 0x2e 0x04>;

			gpe0-gpio-bank {
				gpio-controller;
				#gpio-cells = <0x02>;
				interrupt-controller;
				#interrupt-cells = <0x02>;
			};

			gpe1-gpio-bank {
				gpio-controller;
				#gpio-cells = <0x02>;
				interrupt-controller;
				#interrupt-cells = <0x02>;
			};

			gpf0-gpio-bank {
				gpio-controller;
				#gpio-cells = <0x02>;
				interrupt-controller;
				#interrupt-cells = <0x02>;
			};

			gpf1-gpio-bank {
				gpio-controller;
				#gpio-cells = <0x02>;
				interrupt-controller;
				#interrupt-cells = <0x02>;
			};

			gpg0-gpio-bank {
				gpio-controller;
				#gpio-cells = <0x02>;
				interrupt-controller;
				#interrupt-cells = <0x02>;
			};

			gpg1-gpio-bank {
				gpio-controller;
				#gpio-cells = <0x02>;
				interrupt-controller;
				#interrupt-cells = <0x02>;
			};

			gpg2-gpio-bank {
				gpio-controller;
				#gpio-cells = <0x02>;
				interrupt-controller;
				#interrupt-cells = <0x02>;
			};

			gpj4-gpio-bank {
				gpio-controller;
				#gpio-cells = <0x02>;
				interrupt-controller;
				#interrupt-cells = <0x02>;
			};

			cam-gpio-a-pins {
				samsung,pins = "gpe0-0", "gpe0-1", "gpe0-2", "gpe0-3", "gpe0-4", "gpe0-5", "gpe0-6", "gpe0-7", "gpe1-0", "gpe1-1";
				samsung,pin-function = <0x02>;
				samsung,pin-pud = <0x00>;
				samsung,pin-drv = <0x00>;
			};

			cam-gpio-b-pins {
				samsung,pins = "gpf0-0", "gpf0-1", "gpf0-2", "gpf0-3", "gpf1-0", "gpf1-1", "gpf1-2", "gpf1-3";
				samsung,pin-function = <0x03>;
				samsung,pin-pud = <0x00>;
				samsung,pin-drv = <0x00>;
			};

			cam-i2c2-bus-pins {
				samsung,pins = "gpf0-4", "gpf0-5";
				samsung,pin-function = <0x02>;
				samsung,pin-pud = <0x03>;
				samsung,pin-drv = <0x00>;
			};

			cam-spi1-bus-pins {
				samsung,pins = "gpe0-4", "gpe0-5", "gpf0-2", "gpf0-3";
				samsung,pin-function = <0x04>;
				samsung,pin-pud = <0x00>;
				samsung,pin-drv = <0x00>;
			};

			cam-i2c1-bus-pins {
				samsung,pins = "gpf0-2", "gpf0-3";
				samsung,pin-function = <0x02>;
				samsung,pin-pud = <0x03>;
				samsung,pin-drv = <0x00>;
			};

			cam-i2c0-bus-pins {
				samsung,pins = "gpf0-0", "gpf0-1";
				samsung,pin-function = <0x02>;
				samsung,pin-pud = <0x03>;
				samsung,pin-drv = <0x00>;
			};

			cam-spi0-bus-pins {
				samsung,pins = "gpf1-0", "gpf1-1", "gpf1-2", "gpf1-3";
				samsung,pin-function = <0x02>;
				samsung,pin-pud = <0x00>;
				samsung,pin-drv = <0x00>;
			};

			cam-bayrgb-bus-pins {
				samsung,pins = "gpg0-0", "gpg0-1", "gpg0-2", "gpg0-3", "gpg0-4", "gpg0-5", "gpg0-6", "gpg0-7", "gpg1-0", "gpg1-1", "gpg1-2", "gpg1-3", "gpg1-4", "gpg1-5", "gpg1-6", "gpg1-7", "gpg2-0";
				samsung,pin-function = <0x02>;
				samsung,pin-pud = <0x00>;
				samsung,pin-drv = <0x00>;
			};
		};

		pinctrl@14010000 {
			compatible = "samsung,exynos5420-pinctrl";
			reg = <0x14010000 0x1000>;
			interrupts = <0x00 0x32 0x04>;

			gpa0-gpio-bank {
				gpio-controller;
				#gpio-cells = <0x02>;
				interrupt-controller;
				#interrupt-cells = <0x02>;
			};

			gpa1-gpio-bank {
				gpio-controller;
				#gpio-cells = <0x02>;
				interrupt-controller;
				#interrupt-cells = <0x02>;
			};

			gpa2-gpio-bank {
				gpio-controller;
				#gpio-cells = <0x02>;
				interrupt-controller;
				#interrupt-cells = <0x02>;
			};

			gpb0-gpio-bank {
				gpio-controller;
				#gpio-cells = <0x02>;
				interrupt-controller;
				#interrupt-cells = <0x02>;
			};

			gpb1-gpio-bank {
				gpio-controller;
				#gpio-cells = <0x02>;
				interrupt-controller;
				#interrupt-cells = <0x02>;
			};

			gpb2-gpio-bank {
				gpio-controller;
				#gpio-cells = <0x02>;
				interrupt-controller;
				#interrupt-cells = <0x02>;
			};

			gpb3-gpio-bank {
				gpio-controller;
				#gpio-cells = <0x02>;
				interrupt-controller;
				#interrupt-cells = <0x02>;
			};

			gpb4-gpio-bank {
				gpio-controller;
				#gpio-cells = <0x02>;
				interrupt-controller;
				#interrupt-cells = <0x02>;
			};

			gph0-gpio-bank {
				gpio-controller;
				#gpio-cells = <0x02>;
				interrupt-controller;
				#interrupt-cells = <0x02>;
			};

			uart0-data-pins {
				samsung,pins = "gpa0-0", "gpa0-1";
				samsung,pin-function = <0x02>;
				samsung,pin-pud = <0x00>;
				samsung,pin-drv = <0x00>;
			};

			uart0-fctl-pins {
				samsung,pins = "gpa0-2", "gpa0-3";
				samsung,pin-function = <0x02>;
				samsung,pin-pud = <0x00>;
				samsung,pin-drv = <0x00>;
			};

			uart1-data-pins {
				samsung,pins = "gpa0-4", "gpa0-5";
				samsung,pin-function = <0x02>;
				samsung,pin-pud = <0x00>;
				samsung,pin-drv = <0x00>;
			};

			uart1-fctl-pins {
				samsung,pins = "gpa0-6", "gpa0-7";
				samsung,pin-function = <0x02>;
				samsung,pin-pud = <0x00>;
				samsung,pin-drv = <0x00>;
			};

			i2c2-bus-pins {
				samsung,pins = "gpa0-6", "gpa0-7";
				samsung,pin-function = <0x03>;
				samsung,pin-pud = <0x03>;
				samsung,pin-drv = <0x00>;
				phandle = <0x08>;
			};

			uart2-data-pins {
				samsung,pins = "gpa1-0", "gpa1-1";
				samsung,pin-function = <0x02>;
				samsung,pin-pud = <0x00>;
				samsung,pin-drv = <0x00>;
			};

			uart2-fctl-pins {
				samsung,pins = "gpa1-2", "gpa1-3";
				samsung,pin-function = <0x02>;
				samsung,pin-pud = <0x00>;
				samsung,pin-drv = <0x00>;
			};

			i2c3-bus-pins {
				samsung,pins = "gpa1-2", "gpa1-3";
				samsung,pin-function = <0x03>;
				samsung,pin-pud = <0x03>;
				samsung,pin-drv = <0x00>;
				phandle = <0x09>;
			};

			uart3-data-pins {
				samsung,pins = "gpa1-4", "gpa1-5";
				samsung,pin-function = <0x02>;
				samsung,pin-pud = <0x00>;
				samsung,pin-drv = <0x00>;
			};

			spi0-bus-pins {
				samsung,pins = "gpa2-0", "gpa2-1", "gpa2-2", "gpa2-3";
				samsung,pin-function = <0x02>;
				samsung,pin-pud = <0x03>;
				samsung,pin-drv = <0x00>;
				phandle = <0x46>;
			};

			spi1-bus-pins {
				samsung,pins = "gpa2-4", "gpa2-6", "gpa2-7";
				samsung,pin-function = <0x02>;
				samsung,pin-pud = <0x03>;
				samsung,pin-drv = <0x00>;
				phandle = <0x47>;
			};

			i2c4-hs-bus-pins {
				samsung,pins = "gpa2-0", "gpa2-1";
				samsung,pin-function = <0x03>;
				samsung,pin-pud = <0x03>;
				samsung,pin-drv = <0x00>;
				phandle = <0x16>;
			};

			i2c5-hs-bus-pins {
				samsung,pins = "gpa2-2", "gpa2-3";
				samsung,pin-function = <0x03>;
				samsung,pin-pud = <0x03>;
				samsung,pin-drv = <0x00>;
				phandle = <0x1b>;
			};

			i2s1-bus-pins {
				samsung,pins = "gpb0-0", "gpb0-1", "gpb0-2", "gpb0-3", "gpb0-4";
				samsung,pin-function = <0x02>;
				samsung,pin-pud = <0x00>;
				samsung,pin-drv = <0x00>;
				phandle = <0x44>;
			};

			pcm1-bus-pins {
				samsung,pins = "gpb0-0", "gpb0-1", "gpb0-2", "gpb0-3", "gpb0-4";
				samsung,pin-function = <0x03>;
				samsung,pin-pud = <0x00>;
				samsung,pin-drv = <0x00>;
			};

			i2s2-bus-pins {
				samsung,pins = "gpb1-0", "gpb1-1", "gpb1-2", "gpb1-3", "gpb1-4";
				samsung,pin-function = <0x02>;
				samsung,pin-pud = <0x00>;
				samsung,pin-drv = <0x00>;
				phandle = <0x45>;
			};

			pcm2-bus-pins {
				samsung,pins = "gpb1-0", "gpb1-1", "gpb1-2", "gpb1-3", "gpb1-4";
				samsung,pin-function = <0x03>;
				samsung,pin-pud = <0x00>;
				samsung,pin-drv = <0x00>;
			};

			spdif-bus-pins {
				samsung,pins = "gpb1-0", "gpb1-1";
				samsung,pin-function = <0x04>;
				samsung,pin-pud = <0x00>;
				samsung,pin-drv = <0x00>;
			};

			spi2-bus-pins {
				samsung,pins = "gpb1-1", "gpb1-3", "gpb1-4";
				samsung,pin-function = <0x05>;
				samsung,pin-pud = <0x03>;
				samsung,pin-drv = <0x00>;
				phandle = <0x48>;
			};

			i2c6-hs-bus-pins {
				samsung,pins = "gpb1-3", "gpb1-4";
				samsung,pin-function = <0x04>;
				samsung,pin-pud = <0x03>;
				samsung,pin-drv = <0x00>;
				phandle = <0x1c>;
			};

			pwm0-out-pins {
				samsung,pins = "gpb2-0";
				samsung,pin-function = <0x02>;
				samsung,pin-pud = <0x00>;
				samsung,pin-drv = <0x00>;
				phandle = <0x0a>;
			};

			pwm1-out-pins {
				samsung,pins = "gpb2-1";
				samsung,pin-function = <0x02>;
				samsung,pin-pud = <0x00>;
				samsung,pin-drv = <0x00>;
			};

			pwm2-out-pins {
				samsung,pins = "gpb2-2";
				samsung,pin-function = <0x02>;
				samsung,pin-pud = <0x00>;
				samsung,pin-drv = <0x00>;
				phandle = <0x0b>;
			};

			pwm3-out-pins {
				samsung,pins = "gpb2-3";
				samsung,pin-function = <0x02>;
				samsung,pin-pud = <0x00>;
				samsung,pin-drv = <0x00>;
			};

			i2c7-hs-bus-pins {
				samsung,pins = "gpb2-2", "gpb2-3";
				samsung,pin-function = <0x03>;
				samsung,pin-pud = <0x03>;
				samsung,pin-drv = <0x00>;
				phandle = <0x1d>;
			};

			i2c0-bus-pins {
				samsung,pins = "gpb3-0", "gpb3-1";
				samsung,pin-function = <0x02>;
				samsung,pin-pud = <0x03>;
				samsung,pin-drv = <0x00>;
				phandle = <0x06>;
			};

			i2c1-bus-pins {
				samsung,pins = "gpb3-2", "gpb3-3";
				samsung,pin-function = <0x02>;
				samsung,pin-pud = <0x03>;
				samsung,pin-drv = <0x00>;
				phandle = <0x07>;
			};

			i2c8-hs-bus-pins {
				samsung,pins = "gpb3-4", "gpb3-5";
				samsung,pin-function = <0x02>;
				samsung,pin-pud = <0x03>;
				samsung,pin-drv = <0x00>;
				phandle = <0x4a>;
			};

			i2c9-hs-bus-pins {
				samsung,pins = "gpb3-6", "gpb3-7";
				samsung,pin-function = <0x02>;
				samsung,pin-pud = <0x03>;
				samsung,pin-drv = <0x00>;
				phandle = <0x4b>;
			};

			i2c10-hs-bus-pins {
				samsung,pins = "gpb4-0", "gpb4-1";
				samsung,pin-function = <0x02>;
				samsung,pin-pud = <0x03>;
				samsung,pin-drv = <0x00>;
				phandle = <0x4c>;
			};
		};

		pinctrl@3860000 {
			compatible = "samsung,exynos5420-pinctrl";
			reg = <0x3860000 0x1000>;
			interrupts = <0x00 0x2f 0x04>;
			power-domains = <0x23>;

			gpz-gpio-bank {
				gpio-controller;
				#gpio-cells = <0x02>;
				interrupt-controller;
				#interrupt-cells = <0x02>;
			};

			i2s0-bus-pins {
				samsung,pins = "gpz-0", "gpz-1", "gpz-2", "gpz-3", "gpz-4", "gpz-5", "gpz-6";
				samsung,pin-function = <0x02>;
				samsung,pin-pud = <0x00>;
				samsung,pin-drv = <0x00>;
				phandle = <0x42>;
			};
		};

		dma-controller@3880000 {
			compatible = "arm,pl330", "arm,primecell";
			reg = <0x3880000 0x1000>;
			interrupts = <0x00 0x6e 0x04>;
			clocks = <0x40 0x0a>;
			clock-names = "apb_pclk";
			#dma-cells = <0x01>;
			power-domains = <0x23>;
			phandle = <0x41>;
		};

		dma-controller@121a0000 {
			compatible = "arm,pl330", "arm,primecell";
			reg = <0x121a0000 0x1000>;
			interrupts = <0x00 0x22 0x04>;
			clocks = <0x02 0x16a>;
			clock-names = "apb_pclk";
			#dma-cells = <0x01>;
			phandle = <0x03>;
		};

		dma-controller@121b0000 {
			compatible = "arm,pl330", "arm,primecell";
			reg = <0x121b0000 0x1000>;
			interrupts = <0x00 0x23 0x04>;
			clocks = <0x02 0x16b>;
			clock-names = "apb_pclk";
			#dma-cells = <0x01>;
			phandle = <0x04>;
		};

		dma-controller@10800000 {
			compatible = "arm,pl330", "arm,primecell";
			reg = <0x10800000 0x1000>;
			interrupts = <0x00 0x21 0x04>;
			clocks = <0x02 0x1d9>;
			clock-names = "apb_pclk";
			#dma-cells = <0x01>;
		};

		dma-controller@11c10000 {
			compatible = "arm,pl330", "arm,primecell";
			reg = <0x11c10000 0x1000>;
			interrupts = <0x00 0x7c 0x04>;
			clocks = <0x02 0x1ba>;
			clock-names = "apb_pclk";
			#dma-cells = <0x01>;
			status = "disabled";
		};

		i2s@3830000 {
			compatible = "samsung,exynos5420-i2s";
			reg = <0x3830000 0x100>;
			dmas = <0x41 0x00 0x41 0x02 0x41 0x01>;
			dma-names = "tx", "rx", "tx-sec";
			clocks = <0x40 0x06 0x40 0x06 0x40 0x07>;
			clock-names = "iis", "i2s_opclk0", "i2s_opclk1";
			#clock-cells = <0x01>;
			clock-output-names = "i2s_cdclk0";
			#sound-dai-cells = <0x01>;
			samsung,idma-addr = <0x3000000>;
			pinctrl-names = "default";
			pinctrl-0 = <0x42>;
			power-domains = <0x23>;
			status = "okay";
			assigned-clocks = <0x02 0x291 0x02 0x292 0x02 0x293 0x40 0x00 0x40 0x01 0x43 0x01 0x40 0x02 0x40 0x03 0x40 0x04>;
			assigned-clock-parents = <0x02 0x05 0x02 0x291 0x02 0x292 0x02 0x9f 0x40 0x00 0x40 0x07>;
			assigned-clock-rates = <0x00 0x00 0x00 0x00 0x00 0x00 0xbb80001 0x5dc0001 0xbb80000>;
			phandle = <0x43>;
		};

		i2s@12d60000 {
			compatible = "samsung,exynos5420-i2s";
			reg = <0x12d60000 0x100>;
			dmas = <0x04 0x0c 0x04 0x0b>;
			dma-names = "tx", "rx";
			clocks = <0x02 0x113 0x02 0x8a>;
			clock-names = "iis", "i2s_opclk0";
			#clock-cells = <0x01>;
			clock-output-names = "i2s_cdclk1";
			#sound-dai-cells = <0x01>;
			pinctrl-names = "default";
			pinctrl-0 = <0x44>;
			status = "disabled";
		};

		i2s@12d70000 {
			compatible = "samsung,exynos5420-i2s";
			reg = <0x12d70000 0x100>;
			dmas = <0x03 0x0c 0x03 0x0b>;
			dma-names = "tx", "rx";
			clocks = <0x02 0x114 0x02 0x8b>;
			clock-names = "iis", "i2s_opclk0";
			#clock-cells = <0x01>;
			clock-output-names = "i2s_cdclk2";
			#sound-dai-cells = <0x01>;
			pinctrl-names = "default";
			pinctrl-0 = <0x45>;
			status = "disabled";
		};

		spi@12d20000 {
			compatible = "samsung,exynos4210-spi";
			reg = <0x12d20000 0x100>;
			interrupts = <0x00 0x44 0x04>;
			dmas = <0x03 0x05 0x03 0x04>;
			dma-names = "tx", "rx";
			#address-cells = <0x01>;
			#size-cells = <0x00>;
			pinctrl-names = "default";
			pinctrl-0 = <0x46>;
			clocks = <0x02 0x10f 0x02 0x87>;
			clock-names = "spi", "spi_busclk0";
			fifo-depth = <0x100>;
			status = "disabled";
		};

		spi@12d30000 {
			compatible = "samsung,exynos4210-spi";
			reg = <0x12d30000 0x100>;
			interrupts = <0x00 0x45 0x04>;
			dmas = <0x04 0x05 0x04 0x04>;
			dma-names = "tx", "rx";
			#address-cells = <0x01>;
			#size-cells = <0x00>;
			pinctrl-names = "default";
			pinctrl-0 = <0x47>;
			clocks = <0x02 0x110 0x02 0x88>;
			clock-names = "spi", "spi_busclk0";
			fifo-depth = <0x40>;
			status = "disabled";
		};

		spi@12d40000 {
			compatible = "samsung,exynos4210-spi";
			reg = <0x12d40000 0x100>;
			interrupts = <0x00 0x46 0x04>;
			dmas = <0x03 0x07 0x03 0x06>;
			dma-names = "tx", "rx";
			#address-cells = <0x01>;
			#size-cells = <0x00>;
			pinctrl-names = "default";
			pinctrl-0 = <0x48>;
			clocks = <0x02 0x111 0x02 0x89>;
			clock-names = "spi", "spi_busclk0";
			fifo-depth = <0x40>;
			status = "disabled";
		};

		dsi@14500000 {
			compatible = "samsung,exynos5422-mipi-dsi";
			reg = <0x14500000 0x10000>;
			interrupts = <0x00 0x52 0x04>;
			phys = <0x49 0x01>;
			phy-names = "dsim";
			clocks = <0x02 0x19b 0x02 0x92>;
			clock-names = "bus_clk", "pll_clk";
			#address-cells = <0x01>;
			#size-cells = <0x00>;
			status = "disabled";
		};

		i2c@12e00000 {
			compatible = "samsung,exynos5250-hsi2c";
			reg = <0x12e00000 0x1000>;
			interrupts = <0x00 0x57 0x04>;
			#address-cells = <0x01>;
			#size-cells = <0x00>;
			pinctrl-names = "default";
			pinctrl-0 = <0x4a>;
			clocks = <0x02 0x119>;
			clock-names = "hsi2c";
			status = "disabled";
		};

		i2c@12e10000 {
			compatible = "samsung,exynos5250-hsi2c";
			reg = <0x12e10000 0x1000>;
			interrupts = <0x00 0x58 0x04>;
			#address-cells = <0x01>;
			#size-cells = <0x00>;
			pinctrl-names = "default";
			pinctrl-0 = <0x4b>;
			clocks = <0x02 0x11a>;
			clock-names = "hsi2c";
			status = "disabled";
		};

		i2c@12e20000 {
			compatible = "samsung,exynos5250-hsi2c";
			reg = <0x12e20000 0x1000>;
			interrupts = <0x00 0xcb 0x04>;
			#address-cells = <0x01>;
			#size-cells = <0x00>;
			pinctrl-names = "default";
			pinctrl-0 = <0x4c>;
			clocks = <0x02 0x11b>;
			clock-names = "hsi2c";
			status = "disabled";
		};

		hdmi@14530000 {
			compatible = "samsung,exynos5420-hdmi";
			reg = <0x14530000 0x70000>;
			interrupts = <0x00 0x5f 0x04>;
			clocks = <0x02 0x19d 0x02 0x8f 0x02 0x300 0x02 0x9e 0x02 0x280>;
			clock-names = "hdmi", "sclk_hdmi", "sclk_pixel", "sclk_hdmiphy", "mout_hdmi";
			phy = <0x4d>;
			samsung,syscon-phandle = <0x0d>;
			status = "okay";
			power-domains = <0x0f>;
			#sound-dai-cells = <0x00>;
			ddc = <0x4e>;
			hpd-gpios = <0x4f 0x07 0x00>;
			pinctrl-names = "default";
			pinctrl-0 = <0x50>;
			vdd_osc-supply = <0x51>;
			vdd_pll-supply = <0x52>;
			vdd-supply = <0x52>;
			phandle = <0x53>;
		};

		hdmi-phy@145d0000 {
			reg = <0x145d0000 0x20>;
			phandle = <0x4d>;
		};

		cec@101b0000 {
			compatible = "samsung,s5p-cec";
			reg = <0x101b0000 0x200>;
			interrupts = <0x00 0x72 0x04>;
			clocks = <0x02 0x139>;
			clock-names = "hdmicec";
			samsung,syscon-phandle = <0x0d>;
			hdmi-phandle = <0x53>;
			pinctrl-names = "default";
			pinctrl-0 = <0x54>;
			status = "okay";
			needs-hpd;
		};

		mixer@14450000 {
			compatible = "samsung,exynos5420-mixer";
			reg = <0x14450000 0x10000>;
			interrupts = <0x00 0x5e 0x04>;
			clocks = <0x02 0x1af 0x02 0x19d 0x02 0x8f>;
			clock-names = "mixer", "hdmi", "sclk_hdmi";
			power-domains = <0x0f>;
			iommus = <0x55>;
			status = "okay";
		};

		rotator@11c00000 {
			compatible = "samsung,exynos5250-rotator";
			reg = <0x11c00000 0x64>;
			interrupts = <0x00 0x54 0x04>;
			clocks = <0x02 0x1b9>;
			clock-names = "rotator";
			iommus = <0x56>;
		};

		video-scaler@13e00000 {
			compatible = "samsung,exynos5420-gsc", "samsung,exynos5-gsc";
			reg = <0x13e00000 0x1000>;
			interrupts = <0x00 0x55 0x04>;
			clocks = <0x02 0x1d1>;
			clock-names = "gscl";
			power-domains = <0x57>;
			iommus = <0x58>;
		};

		video-scaler@13e10000 {
			compatible = "samsung,exynos5420-gsc", "samsung,exynos5-gsc";
			reg = <0x13e10000 0x1000>;
			interrupts = <0x00 0x56 0x04>;
			clocks = <0x02 0x1d2>;
			clock-names = "gscl";
			power-domains = <0x57>;
			iommus = <0x59>;
		};

		gpu@11800000 {
			compatible = "samsung,exynos5420-mali", "arm,mali-t628";
			reg = <0x11800000 0x5000>;
			interrupts = <0x00 0xdb 0x04 0x00 0x4a 0x04 0x00 0x75 0x04>;
			interrupt-names = "job", "mmu", "gpu";
			clocks = <0x02 0x1f5>;
			clock-names = "core";
			power-domains = <0x5a>;
			operating-points-v2 = <0x5b>;
			status = "okay";
			#cooling-cells = <0x02>;
			mali-supply = <0x5c>;
			phandle = <0xa0>;

			opp-table {
				compatible = "operating-points-v2";
				phandle = <0x5b>;

				opp-177000000 {
					opp-hz = <0x00 0xa8cce40>;
					opp-microvolt = <0xc65d4>;
				};

				opp-266000000 {
					opp-hz = <0x00 0xfdad680>;
					opp-microvolt = <0xd2924>;
				};

				opp-350000000 {
					opp-hz = <0x00 0x14dc9380>;
					opp-microvolt = <0xdec74>;
				};

				opp-420000000 {
					opp-hz = <0x00 0x1908b100>;
					opp-microvolt = <0xeafc4>;
				};

				opp-480000000 {
					opp-hz = <0x00 0x1c9c3800>;
					opp-microvolt = <0xf4240>;
				};

				opp-543000000 {
					opp-hz = <0x00 0x205d85c0>;
					opp-microvolt = <0xfd4bc>;
				};

				opp-600000000 {
					opp-hz = <0x00 0x23c34600>;
					opp-microvolt = <0x118c30>;
				};
			};
		};

		scaler@12800000 {
			compatible = "samsung,exynos5420-scaler";
			reg = <0x12800000 0x1294>;
			interrupts = <0x00 0xdc 0x04>;
			clocks = <0x02 0x17d>;
			clock-names = "mscl";
			power-domains = <0x5d>;
			iommus = <0x5e 0x5f>;
		};

		scaler@12810000 {
			compatible = "samsung,exynos5420-scaler";
			reg = <0x12810000 0x1294>;
			interrupts = <0x00 0xdd 0x04>;
			clocks = <0x02 0x17e>;
			clock-names = "mscl";
			power-domains = <0x5d>;
			iommus = <0x60 0x61>;
		};

		scaler@12820000 {
			compatible = "samsung,exynos5420-scaler";
			reg = <0x12820000 0x1294>;
			interrupts = <0x00 0xde 0x04>;
			clocks = <0x02 0x17f>;
			clock-names = "mscl";
			power-domains = <0x5d>;
			iommus = <0x62 0x63>;
		};

		jpeg@11f50000 {
			compatible = "samsung,exynos5420-jpeg";
			reg = <0x11f50000 0x1000>;
			interrupts = <0x00 0x59 0x04>;
			clock-names = "jpeg";
			clocks = <0x02 0x1c3>;
			iommus = <0x64>;
		};

		jpeg@11f60000 {
			compatible = "samsung,exynos5420-jpeg";
			reg = <0x11f60000 0x1000>;
			interrupts = <0x00 0xa8 0x04>;
			clock-names = "jpeg";
			clocks = <0x02 0x1c4>;
			iommus = <0x65>;
		};

		system-controller@10040000 {
			compatible = "samsung,exynos5420-pmu", "simple-mfd", "syscon";
			reg = <0x10040000 0x5000>;
			clock-names = "clkout16";
			clocks = <0x02 0x01>;
			#clock-cells = <0x01>;
			interrupt-controller;
			#interrupt-cells = <0x03>;
			interrupt-parent = <0x01>;
			phandle = <0x0d>;

			dp-phy {
				compatible = "samsung,exynos5420-dp-video-phy";
				#phy-cells = <0x00>;
				phandle = <0x12>;
			};

			mipi-phy {
				compatible = "samsung,exynos5420-mipi-video-phy";
				#phy-cells = <0x01>;
				phandle = <0x49>;
			};

			syscon-poweroff {
				compatible = "syscon-poweroff";
				regmap = <0x0d>;
				offset = <0x330c>;
				mask = <0x5200>;
			};

			syscon-reboot {
				compatible = "syscon-reboot";
				regmap = <0x0d>;
				offset = <0x400>;
				mask = <0x01>;
			};
		};

		tmu@10060000 {
			compatible = "samsung,exynos5420-tmu";
			reg = <0x10060000 0x100>;
			interrupts = <0x00 0x41 0x04>;
			clocks = <0x02 0x13e>;
			clock-names = "tmu_apbif";
			#thermal-sensor-cells = <0x00>;
			vtmu-supply = <0x51>;
			phandle = <0x82>;
		};

		tmu@10064000 {
			compatible = "samsung,exynos5420-tmu";
			reg = <0x10064000 0x100>;
			interrupts = <0x00 0xb7 0x04>;
			clocks = <0x02 0x13e>;
			clock-names = "tmu_apbif";
			#thermal-sensor-cells = <0x00>;
			vtmu-supply = <0x51>;
			phandle = <0x89>;
		};

		tmu@10068000 {
			compatible = "samsung,exynos5420-tmu-ext-triminfo";
			reg = <0x10068000 0x100 0x1006c000 0x04>;
			interrupts = <0x00 0xb8 0x04>;
			clocks = <0x02 0x13e 0x02 0x13e>;
			clock-names = "tmu_apbif", "tmu_triminfo_apbif";
			#thermal-sensor-cells = <0x00>;
			vtmu-supply = <0x51>;
			phandle = <0x8f>;
		};

		tmu@1006c000 {
			compatible = "samsung,exynos5420-tmu-ext-triminfo";
			reg = <0x1006c000 0x100 0x100a0000 0x04>;
			interrupts = <0x00 0xb9 0x04>;
			clocks = <0x02 0x13e 0x02 0x13f>;
			clock-names = "tmu_apbif", "tmu_triminfo_apbif";
			#thermal-sensor-cells = <0x00>;
			vtmu-supply = <0x51>;
			phandle = <0x95>;
		};

		tmu@100a0000 {
			compatible = "samsung,exynos5420-tmu-ext-triminfo";
			reg = <0x100a0000 0x100 0x10068000 0x04>;
			interrupts = <0x00 0xd7 0x04>;
			clocks = <0x02 0x13f 0x02 0x13e>;
			clock-names = "tmu_apbif", "tmu_triminfo_apbif";
			#thermal-sensor-cells = <0x00>;
			vtmu-supply = <0x51>;
			phandle = <0x9b>;
		};

		sysmmu@10a60000 {
			compatible = "samsung,exynos-sysmmu";
			reg = <0x10a60000 0x1000>;
			interrupt-parent = <0x0e>;
			interrupts = <0x18 0x05>;
			clock-names = "sysmmu", "master";
			clocks = <0x02 0x1f7 0x02 0x1e1>;
			#iommu-cells = <0x00>;
			phandle = <0x13>;
		};

		sysmmu@10a70000 {
			compatible = "samsung,exynos-sysmmu";
			reg = <0x10a70000 0x1000>;
			interrupt-parent = <0x0e>;
			interrupts = <0x16 0x02>;
			clock-names = "sysmmu", "master";
			clocks = <0x02 0x1f7 0x02 0x1e1>;
			#iommu-cells = <0x00>;
			phandle = <0x14>;
		};

		sysmmu@14650000 {
			compatible = "samsung,exynos-sysmmu";
			reg = <0x14650000 0x1000>;
			interrupt-parent = <0x0e>;
			interrupts = <0x07 0x04>;
			clock-names = "sysmmu", "master";
			clocks = <0x02 0x1f6 0x02 0x1af>;
			power-domains = <0x0f>;
			#iommu-cells = <0x00>;
			phandle = <0x55>;
		};

		sysmmu@13e80000 {
			compatible = "samsung,exynos-sysmmu";
			reg = <0x13e80000 0x1000>;
			interrupt-parent = <0x0e>;
			interrupts = <0x02 0x00>;
			clock-names = "sysmmu", "master";
			clocks = <0x02 0x1cd 0x02 0x1d1>;
			power-domains = <0x57>;
			#iommu-cells = <0x00>;
			phandle = <0x58>;
		};

		sysmmu@13e90000 {
			compatible = "samsung,exynos-sysmmu";
			reg = <0x13e90000 0x1000>;
			interrupt-parent = <0x0e>;
			interrupts = <0x02 0x02>;
			clock-names = "sysmmu", "master";
			clocks = <0x02 0x1ce 0x02 0x1d2>;
			power-domains = <0x57>;
			#iommu-cells = <0x00>;
			phandle = <0x59>;
		};

		sysmmu@12880000 {
			compatible = "samsung,exynos-sysmmu";
			reg = <0x12880000 0x1000>;
			interrupt-parent = <0x0e>;
			interrupts = <0x16 0x04>;
			clock-names = "sysmmu", "master";
			clocks = <0x02 0x180 0x02 0x17d>;
			power-domains = <0x5d>;
			#iommu-cells = <0x00>;
			phandle = <0x5e>;
		};

		sysmmu@12890000 {
			compatible = "samsung,exynos-sysmmu";
			reg = <0x12890000 0x1000>;
			interrupts = <0x00 0xba 0x04>;
			clock-names = "sysmmu", "master";
			clocks = <0x02 0x181 0x02 0x17e>;
			power-domains = <0x5d>;
			#iommu-cells = <0x00>;
			phandle = <0x60>;
		};

		sysmmu@128a0000 {
			compatible = "samsung,exynos-sysmmu";
			reg = <0x128a0000 0x1000>;
			interrupts = <0x00 0xbc 0x04>;
			clock-names = "sysmmu", "master";
			clocks = <0x02 0x182 0x02 0x17f>;
			power-domains = <0x5d>;
			#iommu-cells = <0x00>;
			phandle = <0x62>;
		};

		sysmmu@128c0000 {
			compatible = "samsung,exynos-sysmmu";
			reg = <0x128c0000 0x1000>;
			interrupt-parent = <0x0e>;
			interrupts = <0x1b 0x02>;
			clock-names = "sysmmu", "master";
			clocks = <0x02 0x180 0x02 0x17d>;
			power-domains = <0x5d>;
			#iommu-cells = <0x00>;
			phandle = <0x5f>;
		};

		sysmmu@128d0000 {
			compatible = "samsung,exynos-sysmmu";
			reg = <0x128d0000 0x1000>;
			interrupt-parent = <0x0e>;
			interrupts = <0x16 0x06>;
			clock-names = "sysmmu", "master";
			clocks = <0x02 0x181 0x02 0x17e>;
			power-domains = <0x5d>;
			#iommu-cells = <0x00>;
			phandle = <0x61>;
		};

		sysmmu@128e0000 {
			compatible = "samsung,exynos-sysmmu";
			reg = <0x128e0000 0x1000>;
			interrupt-parent = <0x0e>;
			interrupts = <0x13 0x06>;
			clock-names = "sysmmu", "master";
			clocks = <0x02 0x182 0x02 0x17f>;
			power-domains = <0x5d>;
			#iommu-cells = <0x00>;
			phandle = <0x63>;
		};

		sysmmu@11d40000 {
			compatible = "samsung,exynos-sysmmu";
			reg = <0x11d40000 0x1000>;
			interrupt-parent = <0x0e>;
			interrupts = <0x04 0x00>;
			clock-names = "sysmmu", "master";
			clocks = <0x02 0x1bb 0x02 0x1b9>;
			#iommu-cells = <0x00>;
			phandle = <0x56>;
		};

		sysmmu@11f10000 {
			compatible = "samsung,exynos-sysmmu";
			reg = <0x11f10000 0x1000>;
			interrupt-parent = <0x0e>;
			interrupts = <0x04 0x02>;
			clock-names = "sysmmu", "master";
			clocks = <0x02 0x1c5 0x02 0x1c3>;
			#iommu-cells = <0x00>;
			phandle = <0x64>;
		};

		sysmmu@11f20000 {
			compatible = "samsung,exynos-sysmmu";
			reg = <0x11f20000 0x1000>;
			interrupts = <0x00 0xa9 0x04>;
			clock-names = "sysmmu", "master";
			clocks = <0x02 0x1c6 0x02 0x1c4>;
			#iommu-cells = <0x00>;
			phandle = <0x65>;
		};

		sysmmu@11200000 {
			compatible = "samsung,exynos-sysmmu";
			reg = <0x11200000 0x1000>;
			interrupt-parent = <0x0e>;
			interrupts = <0x06 0x02>;
			clock-names = "sysmmu", "master";
			clocks = <0x02 0x192 0x02 0x191>;
			power-domains = <0x24>;
			#iommu-cells = <0x00>;
			phandle = <0x25>;
		};

		sysmmu@11210000 {
			compatible = "samsung,exynos-sysmmu";
			reg = <0x11210000 0x1000>;
			interrupt-parent = <0x0e>;
			interrupts = <0x08 0x05>;
			clock-names = "sysmmu", "master";
			clocks = <0x02 0x193 0x02 0x191>;
			power-domains = <0x24>;
			#iommu-cells = <0x00>;
			phandle = <0x26>;
		};

		sysmmu@14640000 {
			compatible = "samsung,exynos-sysmmu";
			reg = <0x14640000 0x1000>;
			interrupt-parent = <0x0e>;
			interrupts = <0x03 0x02>;
			clock-names = "sysmmu", "master";
			clocks = <0x02 0x1a6 0x02 0x1a5>;
			power-domains = <0x0f>;
			#iommu-cells = <0x00>;
			phandle = <0x10>;
		};

		sysmmu@14680000 {
			compatible = "samsung,exynos-sysmmu";
			reg = <0x14680000 0x1000>;
			interrupt-parent = <0x0e>;
			interrupts = <0x03 0x00>;
			clock-names = "sysmmu", "master";
			clocks = <0x02 0x1a7 0x02 0x1a5>;
			power-domains = <0x0f>;
			#iommu-cells = <0x00>;
			phandle = <0x11>;
		};

		power-domain@10045100 {
			compatible = "samsung,exynos4210-pd";
			reg = <0x10045100 0x20>;
			#power-domain-cells = <0x00>;
			label = "CAM";
		};
	};

	arm-a7-pmu {
		compatible = "arm,cortex-a7-pmu";
		interrupt-parent = <0x01>;
		interrupts = <0x00 0xa0 0x04 0x00 0xa1 0x04 0x00 0xa2 0x04 0x00 0xa3 0x04>;
		status = "okay";
		interrupt-affinity = <0x66 0x67 0x68 0x69>;
	};

	arm-a15-pmu {
		compatible = "arm,cortex-a15-pmu";
		interrupt-parent = <0x0e>;
		interrupts = <0x01 0x02 0x07 0x00 0x10 0x06 0x13 0x02>;
		status = "okay";
		interrupt-affinity = <0x6a 0x6b 0x6c 0x6d>;
	};

	timer {
		compatible = "arm,armv7-timer";
		interrupts = <0x01 0x0d 0xf08 0x01 0x0e 0xf08 0x01 0x0b 0xf08 0x01 0x0a 0xf08>;
		clock-frequency = <0x16e3600>;
	};

	bus-disp1 {
		compatible = "samsung,exynos-bus";
		clocks = <0x02 0x316>;
		clock-names = "bus";
		status = "okay";
		operating-points-v2 = <0x6e>;
		devfreq = <0x6f>;
	};

	bus-disp1-fimd {
		compatible = "samsung,exynos-bus";
		clocks = <0x02 0x314>;
		clock-names = "bus";
		status = "okay";
		operating-points-v2 = <0x70>;
		devfreq = <0x6f>;
	};

	bus-fsys {
		compatible = "samsung,exynos-bus";
		clocks = <0x02 0x308>;
		clock-names = "bus";
		status = "disabled";
	};

	bus-fsys2 {
		compatible = "samsung,exynos-bus";
		clocks = <0x02 0x305>;
		clock-names = "bus";
		status = "okay";
		operating-points-v2 = <0x71>;
		devfreq = <0x6f>;
	};

	bus-fsys-apb {
		compatible = "samsung,exynos-bus";
		clocks = <0x02 0x307>;
		clock-names = "bus";
		status = "okay";
		operating-points-v2 = <0x72>;
		devfreq = <0x6f>;
	};

	bus-g2d {
		compatible = "samsung,exynos-bus";
		clocks = <0x02 0x310>;
		clock-names = "bus";
		status = "okay";
		operating-points-v2 = <0x73>;
		devfreq = <0x6f>;
	};

	bus-g2d-acp {
		compatible = "samsung,exynos-bus";
		clocks = <0x02 0x311>;
		clock-names = "bus";
		status = "okay";
		operating-points-v2 = <0x74>;
		devfreq = <0x6f>;
	};

	bus-gen {
		compatible = "samsung,exynos-bus";
		clocks = <0x02 0x30d>;
		clock-names = "bus";
		status = "okay";
		operating-points-v2 = <0x75>;
		devfreq = <0x6f>;
	};

	bus-gscl-scaler {
		compatible = "samsung,exynos-bus";
		clocks = <0x02 0x315>;
		clock-names = "bus";
		status = "okay";
		operating-points-v2 = <0x76>;
		devfreq = <0x6f>;
	};

	bus-jpeg {
		compatible = "samsung,exynos-bus";
		clocks = <0x02 0x313>;
		clock-names = "bus";
		status = "okay";
		operating-points-v2 = <0x77>;
		devfreq = <0x6f>;
	};

	bus-jpeg-apb {
		compatible = "samsung,exynos-bus";
		clocks = <0x02 0x30e>;
		clock-names = "bus";
		status = "okay";
		operating-points-v2 = <0x78>;
		devfreq = <0x6f>;
	};

	bus-mfc {
		compatible = "samsung,exynos-bus";
		clocks = <0x02 0x30f>;
		clock-names = "bus";
		status = "okay";
		operating-points-v2 = <0x79>;
		devfreq = <0x6f>;
	};

	bus-mscl {
		compatible = "samsung,exynos-bus";
		clocks = <0x02 0x303>;
		clock-names = "bus";
		status = "okay";
		operating-points-v2 = <0x7a>;
		devfreq = <0x6f>;
	};

	bus-noc {
		compatible = "samsung,exynos-bus";
		clocks = <0x02 0x306>;
		clock-names = "bus";
		status = "okay";
		operating-points-v2 = <0x7b>;
		devfreq = <0x6f>;
	};

	bus-peri {
		compatible = "samsung,exynos-bus";
		clocks = <0x02 0x30b>;
		clock-names = "bus";
		status = "okay";
		operating-points-v2 = <0x7c>;
		devfreq = <0x6f>;
	};

	bus-wcore {
		compatible = "samsung,exynos-bus";
		clocks = <0x02 0x301>;
		clock-names = "bus";
		status = "okay";
		operating-points-v2 = <0x7d>;
		devfreq-events = <0x7e 0x7f 0x80 0x81>;
		vdd-supply = <0x19>;
		exynos,saturation-ratio = <0x64>;
		phandle = <0x6f>;
	};

	opp-table-0 {
		compatible = "operating-points-v2";
		opp-shared;
		phandle = <0xa6>;

		opp-1800000000 {
			opp-hz = <0x00 0x6b49d200>;
			opp-microvolt = <0x12e1fc 0x12e1fc 0x16e360>;
			clock-latency-ns = <0x222e0>;
		};

		opp-1700000000 {
			opp-hz = <0x00 0x6553f100>;
			opp-microvolt = <0x1312d0 0x1312d0 0x16e360>;
			clock-latency-ns = <0x222e0>;
		};

		opp-1600000000 {
			opp-hz = <0x00 0x5f5e1000>;
			opp-microvolt = <0x1312d0 0x1312d0 0x16e360>;
			clock-latency-ns = <0x222e0>;
		};

		opp-1500000000 {
			opp-hz = <0x00 0x59682f00>;
			opp-microvolt = <0x10c8e0 0x10c8e0 0x16e360>;
			clock-latency-ns = <0x222e0>;
		};

		opp-1400000000 {
			opp-hz = <0x00 0x53724e00>;
			opp-microvolt = <0x10c8e0 0x10c8e0 0x16e360>;
			clock-latency-ns = <0x222e0>;
		};

		opp-1300000000 {
			opp-hz = <0x00 0x4d7c6d00>;
			opp-microvolt = <0x10c8e0 0x10c8e0 0x16e360>;
			clock-latency-ns = <0x222e0>;
		};

		opp-1200000000 {
			opp-hz = <0x00 0x47868c00>;
			opp-microvolt = <0xf4240 0xf4240 0x16e360>;
			clock-latency-ns = <0x222e0>;
		};

		opp-1100000000 {
			opp-hz = <0x00 0x4190ab00>;
			opp-microvolt = <0xf4240 0xf4240 0x16e360>;
			clock-latency-ns = <0x222e0>;
		};

		opp-1000000000 {
			opp-hz = <0x00 0x3b9aca00>;
			opp-microvolt = <0xf4240 0xf4240 0x16e360>;
			clock-latency-ns = <0x222e0>;
		};

		opp-900000000 {
			opp-hz = <0x00 0x35a4e900>;
			opp-microvolt = <0xf4240 0xf4240 0x16e360>;
			clock-latency-ns = <0x222e0>;
		};

		opp-800000000 {
			opp-hz = <0x00 0x2faf0800>;
			opp-microvolt = <0xdbba0 0xdbba0 0x16e360>;
			clock-latency-ns = <0x222e0>;
		};

		opp-700000000 {
			opp-hz = <0x00 0x29b92700>;
			opp-microvolt = <0xdbba0 0xdbba0 0x16e360>;
			clock-latency-ns = <0x222e0>;
		};

		opp-2000000000 {
			opp-hz = <0x00 0x77359400>;
			opp-microvolt = <0x1406f4 0x1406f4 0x16e360>;
			clock-latency-ns = <0x222e0>;
		};

		opp-1900000000 {
			opp-hz = <0x00 0x713fb300>;
			opp-microvolt = <0x1343a4 0x1343a4 0x16e360>;
			clock-latency-ns = <0x222e0>;
		};

		opp-600000000 {
			opp-hz = <0x00 0x23c34600>;
			opp-microvolt = <0xdbba0 0xdbba0 0x16e360>;
			clock-latency-ns = <0x222e0>;
		};

		opp-500000000 {
			opp-hz = <0x00 0x1dcd6500>;
			opp-microvolt = <0xdbba0 0xdbba0 0x16e360>;
			clock-latency-ns = <0x222e0>;
		};

		opp-400000000 {
			opp-hz = <0x00 0x17d78400>;
			opp-microvolt = <0xdbba0 0xdbba0 0x16e360>;
			clock-latency-ns = <0x222e0>;
		};

		opp-300000000 {
			opp-hz = <0x00 0x11e1a300>;
			opp-microvolt = <0xdbba0 0xdbba0 0x16e360>;
			clock-latency-ns = <0x222e0>;
		};

		opp-200000000 {
			opp-hz = <0x00 0xbebc200>;
			opp-microvolt = <0xdbba0 0xdbba0 0x16e360>;
			clock-latency-ns = <0x222e0>;
		};
	};

	opp-table-1 {
		compatible = "operating-points-v2";
		opp-shared;
		phandle = <0xa3>;

		opp-1300000000 {
			opp-hz = <0x00 0x4d7c6d00>;
			opp-microvolt = <0x1312d0>;
			clock-latency-ns = <0x222e0>;
		};

		opp-1200000000 {
			opp-hz = <0x00 0x47868c00>;
			opp-microvolt = <0x1312d0>;
			clock-latency-ns = <0x222e0>;
		};

		opp-1100000000 {
			opp-hz = <0x00 0x4190ab00>;
			opp-microvolt = <0x1312d0>;
			clock-latency-ns = <0x222e0>;
		};

		opp-1000000000 {
			opp-hz = <0x00 0x3b9aca00>;
			opp-microvolt = <0x10c8e0>;
			clock-latency-ns = <0x222e0>;
		};

		opp-900000000 {
			opp-hz = <0x00 0x35a4e900>;
			opp-microvolt = <0x10c8e0>;
			clock-latency-ns = <0x222e0>;
		};

		opp-800000000 {
			opp-hz = <0x00 0x2faf0800>;
			opp-microvolt = <0x10c8e0>;
			clock-latency-ns = <0x222e0>;
		};

		opp-700000000 {
			opp-hz = <0x00 0x29b92700>;
			opp-microvolt = <0xf4240>;
			clock-latency-ns = <0x222e0>;
		};

		opp-600000000 {
			opp-hz = <0x00 0x23c34600>;
			opp-microvolt = <0xf4240>;
			clock-latency-ns = <0x222e0>;
		};

		opp-1400000000 {
			opp-hz = <0x00 0x53724e00>;
			opp-microvolt = <0x137478>;
			clock-latency-ns = <0x222e0>;
		};

		opp-500000000 {
			opp-hz = <0x00 0x1dcd6500>;
			opp-microvolt = <0xf4240>;
			clock-latency-ns = <0x222e0>;
		};

		opp-400000000 {
			opp-hz = <0x00 0x17d78400>;
			opp-microvolt = <0xf4240>;
			clock-latency-ns = <0x222e0>;
		};

		opp-300000000 {
			opp-hz = <0x00 0x11e1a300>;
			opp-microvolt = <0xdbba0>;
			clock-latency-ns = <0x222e0>;
		};

		opp-200000000 {
			opp-hz = <0x00 0xbebc200>;
			opp-microvolt = <0xdbba0>;
			clock-latency-ns = <0x222e0>;
		};
	};

	thermal-zones {

		cpu0-thermal {
			thermal-sensors = <0x82>;
			polling-delay-passive = <0x00>;
			polling-delay = <0x00>;

			trips {

				cpu-alert-0 {
					temperature = <0xc350>;
					hysteresis = <0x1388>;
					type = "active";
					phandle = <0x83>;
				};

				cpu-alert-1 {
					temperature = <0xea60>;
					hysteresis = <0x1388>;
					type = "active";
					phandle = <0x85>;
				};

				cpu-alert-2 {
					temperature = <0x11170>;
					hysteresis = <0x1388>;
					type = "active";
					phandle = <0x86>;
				};

				cpu-crit-0 {
					temperature = <0x1d4c0>;
					hysteresis = <0x00>;
					type = "critical";
				};

				cpu-alert-3 {
					temperature = <0x11170>;
					hysteresis = <0x2710>;
					type = "passive";
					phandle = <0x87>;
				};

				cpu-alert-4 {
					temperature = <0x14c08>;
					hysteresis = <0x2710>;
					type = "passive";
					phandle = <0x88>;
				};
			};

			cooling-maps {

				map0 {
					trip = <0x83>;
					cooling-device = <0x84 0x00 0x01>;
				};

				map1 {
					trip = <0x85>;
					cooling-device = <0x84 0x01 0x02>;
				};

				map2 {
					trip = <0x86>;
					cooling-device = <0x84 0x02 0x03>;
				};

				map3 {
					trip = <0x87>;
					cooling-device = <0x66 0x00 0x02 0x67 0x00 0x02 0x68 0x00 0x02 0x69 0x00 0x02 0x6a 0x00 0x02 0x6b 0x00 0x02 0x6c 0x00 0x02 0x6d 0x00 0x02>;
				};

				map4 {
					trip = <0x88>;
					cooling-device = <0x66 0x03 0x08 0x67 0x03 0x08 0x68 0x03 0x08 0x69 0x03 0x08 0x6a 0x03 0x0e 0x6b 0x03 0x0e 0x6c 0x03 0x0e 0x6d 0x03 0x0e>;
				};
			};
		};

		cpu1-thermal {
			thermal-sensors = <0x89>;
			polling-delay-passive = <0x00>;
			polling-delay = <0x00>;

			trips {

				cpu-alert-0 {
					temperature = <0xc350>;
					hysteresis = <0x1388>;
					type = "active";
					phandle = <0x8a>;
				};

				cpu-alert-1 {
					temperature = <0xea60>;
					hysteresis = <0x1388>;
					type = "active";
					phandle = <0x8b>;
				};

				cpu-alert-2 {
					temperature = <0x11170>;
					hysteresis = <0x1388>;
					type = "active";
					phandle = <0x8c>;
				};

				cpu-crit-0 {
					temperature = <0x1d4c0>;
					hysteresis = <0x00>;
					type = "critical";
				};

				cpu-alert-3 {
					temperature = <0x11170>;
					hysteresis = <0x2710>;
					type = "passive";
					phandle = <0x8d>;
				};

				cpu-alert-4 {
					temperature = <0x14c08>;
					hysteresis = <0x2710>;
					type = "passive";
					phandle = <0x8e>;
				};
			};

			cooling-maps {

				map0 {
					trip = <0x8a>;
					cooling-device = <0x84 0x00 0x01>;
				};

				map1 {
					trip = <0x8b>;
					cooling-device = <0x84 0x01 0x02>;
				};

				map2 {
					trip = <0x8c>;
					cooling-device = <0x84 0x02 0x03>;
				};

				map3 {
					trip = <0x8d>;
					cooling-device = <0x66 0x00 0x02 0x67 0x00 0x02 0x68 0x00 0x02 0x69 0x00 0x02 0x6a 0x00 0x02 0x6b 0x00 0x02 0x6c 0x00 0x02 0x6d 0x00 0x02>;
				};

				map4 {
					trip = <0x8e>;
					cooling-device = <0x66 0x03 0x08 0x67 0x03 0x08 0x68 0x03 0x08 0x69 0x03 0x08 0x6a 0x03 0x0e 0x6b 0x03 0x0e 0x6c 0x03 0x0e 0x6d 0x03 0x0e>;
				};
			};
		};

		cpu2-thermal {
			thermal-sensors = <0x8f>;
			polling-delay-passive = <0x00>;
			polling-delay = <0x00>;

			trips {

				cpu-alert-0 {
					temperature = <0xc350>;
					hysteresis = <0x1388>;
					type = "active";
					phandle = <0x90>;
				};

				cpu-alert-1 {
					temperature = <0xea60>;
					hysteresis = <0x1388>;
					type = "active";
					phandle = <0x91>;
				};

				cpu-alert-2 {
					temperature = <0x11170>;
					hysteresis = <0x1388>;
					type = "active";
					phandle = <0x92>;
				};

				cpu-crit-0 {
					temperature = <0x1d4c0>;
					hysteresis = <0x00>;
					type = "critical";
				};

				cpu-alert-3 {
					temperature = <0x11170>;
					hysteresis = <0x2710>;
					type = "passive";
					phandle = <0x93>;
				};

				cpu-alert-4 {
					temperature = <0x14c08>;
					hysteresis = <0x2710>;
					type = "passive";
					phandle = <0x94>;
				};
			};

			cooling-maps {

				map0 {
					trip = <0x90>;
					cooling-device = <0x84 0x00 0x01>;
				};

				map1 {
					trip = <0x91>;
					cooling-device = <0x84 0x01 0x02>;
				};

				map2 {
					trip = <0x92>;
					cooling-device = <0x84 0x02 0x03>;
				};

				map3 {
					trip = <0x93>;
					cooling-device = <0x66 0x00 0x02 0x67 0x00 0x02 0x68 0x00 0x02 0x69 0x00 0x02 0x6a 0x00 0x02 0x6b 0x00 0x02 0x6c 0x00 0x02 0x6d 0x00 0x02>;
				};

				map4 {
					trip = <0x94>;
					cooling-device = <0x66 0x03 0x08 0x67 0x03 0x08 0x68 0x03 0x08 0x69 0x03 0x08 0x6a 0x03 0x0e 0x6b 0x03 0x0e 0x6c 0x03 0x0e 0x6d 0x03 0x0e>;
				};
			};
		};

		cpu3-thermal {
			thermal-sensors = <0x95>;
			polling-delay-passive = <0x00>;
			polling-delay = <0x00>;

			trips {

				cpu-alert-0 {
					temperature = <0xc350>;
					hysteresis = <0x1388>;
					type = "active";
					phandle = <0x96>;
				};

				cpu-alert-1 {
					temperature = <0xea60>;
					hysteresis = <0x1388>;
					type = "active";
					phandle = <0x97>;
				};

				cpu-alert-2 {
					temperature = <0x11170>;
					hysteresis = <0x1388>;
					type = "active";
					phandle = <0x98>;
				};

				cpu-crit-0 {
					temperature = <0x1d4c0>;
					hysteresis = <0x00>;
					type = "critical";
				};

				cpu-alert-3 {
					temperature = <0x11170>;
					hysteresis = <0x2710>;
					type = "passive";
					phandle = <0x99>;
				};

				cpu-alert-4 {
					temperature = <0x14c08>;
					hysteresis = <0x2710>;
					type = "passive";
					phandle = <0x9a>;
				};
			};

			cooling-maps {

				map0 {
					trip = <0x96>;
					cooling-device = <0x84 0x00 0x01>;
				};

				map1 {
					trip = <0x97>;
					cooling-device = <0x84 0x01 0x02>;
				};

				map2 {
					trip = <0x98>;
					cooling-device = <0x84 0x02 0x03>;
				};

				map3 {
					trip = <0x99>;
					cooling-device = <0x66 0x00 0x02 0x67 0x00 0x02 0x68 0x00 0x02 0x69 0x00 0x02 0x6a 0x00 0x02 0x6b 0x00 0x02 0x6c 0x00 0x02 0x6d 0x00 0x02>;
				};

				map4 {
					trip = <0x9a>;
					cooling-device = <0x66 0x03 0x08 0x67 0x03 0x08 0x68 0x03 0x08 0x69 0x03 0x08 0x6a 0x03 0x0e 0x6b 0x03 0x0e 0x6c 0x03 0x0e 0x6d 0x03 0x0e>;
				};
			};
		};

		gpu-thermal {
			thermal-sensors = <0x9b>;
			polling-delay-passive = <0x00>;
			polling-delay = <0x00>;

			trips {

				cpu-alert-0 {
					temperature = <0x14c08>;
					hysteresis = <0x2710>;
					type = "active";
				};

				cpu-alert-1 {
					temperature = <0x19258>;
					hysteresis = <0x2710>;
					type = "active";
				};

				cpu-alert-2 {
					temperature = <0x1adb0>;
					hysteresis = <0x2710>;
					type = "active";
				};

				cpu-crit-0 {
					temperature = <0x1d4c0>;
					hysteresis = <0x00>;
					type = "critical";
				};

				gpu-alert-0 {
					temperature = <0xc350>;
					hysteresis = <0x1388>;
					type = "active";
					phandle = <0x9c>;
				};

				gpu-alert-1 {
					temperature = <0xea60>;
					hysteresis = <0x1388>;
					type = "active";
					phandle = <0x9d>;
				};

				gpu-alert-2 {
					temperature = <0x11170>;
					hysteresis = <0x1388>;
					type = "active";
					phandle = <0x9e>;
				};

				gpu-crit-0 {
					temperature = <0x1d4c0>;
					hysteresis = <0x00>;
					type = "critical";
				};

				gpu-alert-3 {
					temperature = <0x11170>;
					hysteresis = <0x2710>;
					type = "passive";
					phandle = <0x9f>;
				};

				gpu-alert-4 {
					temperature = <0x14c08>;
					hysteresis = <0x2710>;
					type = "passive";
					phandle = <0xa1>;
				};
			};

			cooling-maps {

				map0 {
					trip = <0x9c>;
					cooling-device = <0x84 0x00 0x01>;
				};

				map1 {
					trip = <0x9d>;
					cooling-device = <0x84 0x01 0x02>;
				};

				map2 {
					trip = <0x9e>;
					cooling-device = <0x84 0x02 0x03>;
				};

				map3 {
					trip = <0x9f>;
					cooling-device = <0xa0 0x00 0x02>;
				};

				map4 {
					trip = <0xa1>;
					cooling-device = <0xa0 0x03 0x06>;
				};
			};
		};
	};

	cpus {
		#address-cells = <0x01>;
		#size-cells = <0x00>;

		cpu-map {

			cluster0 {

				core0 {
					cpu = <0x66>;
				};

				core1 {
					cpu = <0x67>;
				};

				core2 {
					cpu = <0x68>;
				};

				core3 {
					cpu = <0x69>;
				};
			};

			cluster1 {

				core0 {
					cpu = <0x6a>;
				};

				core1 {
					cpu = <0x6b>;
				};

				core2 {
					cpu = <0x6c>;
				};

				core3 {
					cpu = <0x6d>;
				};
			};
		};

		cpu@100 {
			device_type = "cpu";
			compatible = "arm,cortex-a7";
			reg = <0x100>;
			clocks = <0x02 0x0e>;
			clock-frequency = <0x3b9aca00>;
			cci-control-port = <0xa2>;
			operating-points-v2 = <0xa3>;
			#cooling-cells = <0x02>;
			capacity-dmips-mhz = <0x21b>;
			dynamic-power-coefficient = <0x5a>;
			cpu-supply = <0xa4>;
			phandle = <0x66>;
		};

		cpu@101 {
			device_type = "cpu";
			compatible = "arm,cortex-a7";
			reg = <0x101>;
			clocks = <0x02 0x0e>;
			clock-frequency = <0x3b9aca00>;
			cci-control-port = <0xa2>;
			operating-points-v2 = <0xa3>;
			#cooling-cells = <0x02>;
			capacity-dmips-mhz = <0x21b>;
			dynamic-power-coefficient = <0x5a>;
			phandle = <0x67>;
		};

		cpu@102 {
			device_type = "cpu";
			compatible = "arm,cortex-a7";
			reg = <0x102>;
			clocks = <0x02 0x0e>;
			clock-frequency = <0x3b9aca00>;
			cci-control-port = <0xa2>;
			operating-points-v2 = <0xa3>;
			#cooling-cells = <0x02>;
			capacity-dmips-mhz = <0x21b>;
			dynamic-power-coefficient = <0x5a>;
			phandle = <0x68>;
		};

		cpu@103 {
			device_type = "cpu";
			compatible = "arm,cortex-a7";
			reg = <0x103>;
			clocks = <0x02 0x0e>;
			clock-frequency = <0x3b9aca00>;
			cci-control-port = <0xa2>;
			operating-points-v2 = <0xa3>;
			#cooling-cells = <0x02>;
			capacity-dmips-mhz = <0x21b>;
			dynamic-power-coefficient = <0x5a>;
			phandle = <0x69>;
		};

		cpu@0 {
			device_type = "cpu";
			compatible = "arm,cortex-a15";
			reg = <0x00>;
			clocks = <0x02 0x0d>;
			clock-frequency = <0x6b49d200>;
			cci-control-port = <0xa5>;
			operating-points-v2 = <0xa6>;
			#cooling-cells = <0x02>;
			capacity-dmips-mhz = <0x400>;
			dynamic-power-coefficient = <0x136>;
			cpu-supply = <0x1a>;
			phandle = <0x6a>;
		};

		cpu@1 {
			device_type = "cpu";
			compatible = "arm,cortex-a15";
			reg = <0x01>;
			clocks = <0x02 0x0d>;
			clock-frequency = <0x6b49d200>;
			cci-control-port = <0xa5>;
			operating-points-v2 = <0xa6>;
			#cooling-cells = <0x02>;
			capacity-dmips-mhz = <0x400>;
			dynamic-power-coefficient = <0x136>;
			phandle = <0x6b>;
		};

		cpu@2 {
			device_type = "cpu";
			compatible = "arm,cortex-a15";
			reg = <0x02>;
			clocks = <0x02 0x0d>;
			clock-frequency = <0x6b49d200>;
			cci-control-port = <0xa5>;
			operating-points-v2 = <0xa6>;
			#cooling-cells = <0x02>;
			capacity-dmips-mhz = <0x400>;
			dynamic-power-coefficient = <0x136>;
			phandle = <0x6c>;
		};

		cpu@3 {
			device_type = "cpu";
			compatible = "arm,cortex-a15";
			reg = <0x03>;
			clocks = <0x02 0x0d>;
			clock-frequency = <0x6b49d200>;
			cci-control-port = <0xa5>;
			operating-points-v2 = <0xa6>;
			#cooling-cells = <0x02>;
			capacity-dmips-mhz = <0x400>;
			dynamic-power-coefficient = <0x136>;
			phandle = <0x6d>;
		};
	};

	memory@40000000 {
		device_type = "memory";
		reg = <0x40000000 0x7ea00000>;
	};

	chosen {
		stdout-path = "serial2:115200n8";
	};

	firmware@2073000 {
		compatible = "samsung,secure-firmware";
		reg = <0x2073000 0x1000>;
	};

	fixed-rate-clocks {

		oscclk {
			compatible = "samsung,exynos5420-oscclk";
			clock-frequency = <0x16e3600>;
		};
	};

	opp-table-2 {
		compatible = "operating-points-v2";
		phandle = <0x7d>;

		opp00 {
			opp-hz = <0x00 0x5497460>;
			opp-microvolt = <0xe1d48 0xe1d48 0x155cc0>;
		};

		opp01 {
			opp-hz = <0x00 0x7ed6b40>;
			opp-microvolt = <0xe7ef0 0xe7ef0 0x155cc0>;
		};

		opp02 {
			opp-hz = <0x00 0xa92e8c0>;
			opp-microvolt = <0xe7ef0 0xe7ef0 0x155cc0>;
		};

		opp03 {
			opp-hz = <0x00 0xfdad680>;
			opp-microvolt = <0xe7ef0 0xe7ef0 0x155cc0>;
		};

		opp04 {
			opp-hz = <0x00 0x1fb5ad00>;
			opp-microvolt = <0xf4240 0xf4240 0x155cc0>;
		};
	};

	opp-table-3 {
		compatible = "operating-points-v2";
		phandle = <0x7b>;

		opp00 {
			opp-hz = <0x00 0x3f83c40>;
		};

		opp01 {
			opp-hz = <0x00 0x4692680>;
		};

		opp02 {
			opp-hz = <0x00 0x4f64b50>;
		};

		opp03 {
			opp-hz = <0x00 0x69db9c0>;
		};
	};

	opp-table-4 {
		compatible = "operating-points-v2";
		phandle = <0x72>;

		opp00 {
			opp-hz = <0x00 0x69db9c0>;
		};

		opp01 {
			opp-hz = <0x00 0xd3b7380>;
		};
	};

	opp-table-5 {
		compatible = "operating-points-v2";
		phandle = <0x71>;

		opp00 {
			opp-hz = <0x00 0x47868c0>;
		};

		opp01 {
			opp-hz = <0x00 0x7270e00>;
		};

		opp02 {
			opp-hz = <0x00 0xbebc200>;
		};
	};

	opp-table-6 {
		compatible = "operating-points-v2";
		phandle = <0x79>;

		opp00 {
			opp-hz = <0x00 0x4f64b50>;
		};

		opp01 {
			opp-hz = <0x00 0x69db9c0>;
		};

		opp02 {
			opp-hz = <0x00 0x9ec96a0>;
		};

		opp03 {
			opp-hz = <0x00 0xd3b7380>;
		};

		opp04 {
			opp-hz = <0x00 0x13d92d40>;
		};
	};

	opp-table-7 {
		compatible = "operating-points-v2";
		phandle = <0x75>;

		opp00 {
			opp-hz = <0x00 0x5497460>;
		};

		opp01 {
			opp-hz = <0x00 0x7ed6b40>;
		};

		opp02 {
			opp-hz = <0x00 0xa9c1080>;
		};

		opp03 {
			opp-hz = <0x00 0xfdad680>;
		};
	};

	opp-table-8 {
		compatible = "operating-points-v2";
		phandle = <0x7c>;

		opp00 {
			opp-hz = <0x00 0x3f83c40>;
		};
	};

	opp-table-9 {
		compatible = "operating-points-v2";
		phandle = <0x73>;

		opp00 {
			opp-hz = <0x00 0x4f64b50>;
		};

		opp01 {
			opp-hz = <0x00 0x69db9c0>;
		};

		opp02 {
			opp-hz = <0x00 0x9ec96a0>;
		};

		opp03 {
			opp-hz = <0x00 0xd3b7380>;
		};

		opp04 {
			opp-hz = <0x00 0x13d92d40>;
		};
	};

	opp-table-10 {
		compatible = "operating-points-v2";
		phandle = <0x74>;

		opp00 {
			opp-hz = <0x00 0x3f6b5a0>;
		};

		opp01 {
			opp-hz = <0x00 0x7ed6b40>;
		};

		opp02 {
			opp-hz = <0x00 0xa9c1080>;
		};

		opp03 {
			opp-hz = <0x00 0xfdad680>;
		};
	};

	opp-table-11 {
		compatible = "operating-points-v2";
		phandle = <0x77>;

		opp00 {
			opp-hz = <0x00 0x47868c0>;
		};

		opp01 {
			opp-hz = <0x00 0x8f0d180>;
		};

		opp02 {
			opp-hz = <0x00 0xbebc200>;
		};

		opp03 {
			opp-hz = <0x00 0x11e1a300>;
		};
	};

	opp-table-12 {
		compatible = "operating-points-v2";
		phandle = <0x78>;

		opp00 {
			opp-hz = <0x00 0x4f64b50>;
		};

		opp01 {
			opp-hz = <0x00 0x69db9c0>;
		};

		opp02 {
			opp-hz = <0x00 0x7ed6b40>;
		};

		opp03 {
			opp-hz = <0x00 0x9ec96a0>;
		};
	};

	opp-table-13 {
		compatible = "operating-points-v2";
		phandle = <0x70>;

		opp00 {
			opp-hz = <0x00 0x7270e00>;
		};

		opp01 {
			opp-hz = <0x00 0xbebc200>;
		};
	};

	opp-table-14 {
		compatible = "operating-points-v2";
		phandle = <0x6e>;

		opp00 {
			opp-hz = <0x00 0x7270e00>;
		};

		opp01 {
			opp-hz = <0x00 0xbebc200>;
		};

		opp02 {
			opp-hz = <0x00 0x11e1a300>;
		};
	};

	opp-table-15 {
		compatible = "operating-points-v2";
		phandle = <0x76>;

		opp00 {
			opp-hz = <0x00 0x8f0d180>;
		};

		opp01 {
			opp-hz = <0x00 0xbebc200>;
		};

		opp02 {
			opp-hz = <0x00 0x11e1a300>;
		};
	};

	opp-table-16 {
		compatible = "operating-points-v2";
		phandle = <0x7a>;

		opp00 {
			opp-hz = <0x00 0x501bd00>;
		};

		opp01 {
			opp-hz = <0x00 0x9f437c0>;
		};

		opp02 {
			opp-hz = <0x00 0xd3b7380>;
		};

		opp03 {
			opp-hz = <0x00 0x13d92d40>;
		};

		opp04 {
			opp-hz = <0x00 0x27b25a80>;
		};
	};

	opp-table-17 {
		compatible = "operating-points-v2";
		phandle = <0x3e>;

		opp00 {
			opp-hz = <0x00 0x9d5b340>;
			opp-microvolt = <0xd59f8>;
		};

		opp01 {
			opp-hz = <0x00 0xc474f80>;
			opp-microvolt = <0xd59f8>;
		};

		opp02 {
			opp-hz = <0x00 0x10642ac0>;
			opp-microvolt = <0xd59f8>;
		};

		opp03 {
			opp-hz = <0x00 0x189de140>;
			opp-microvolt = <0xd8acc>;
		};

		opp04 {
			opp-hz = <0x00 0x205d85c0>;
			opp-microvolt = <0xe4e1c>;
		};

		opp05 {
			opp-hz = <0x00 0x25bad040>;
			opp-microvolt = <0xf7314>;
		};

		opp06 {
			opp-hz = <0x00 0x2b646600>;
			opp-microvolt = <0xfd4bc>;
		};

		opp07 {
			opp-hz = <0x00 0x312c8040>;
			opp-microvolt = <0x100590>;
		};
	};

	lpddr3 {
		compatible = "samsung,K3QF2F20DB", "jedec,lpddr3";
		density = <0x4000>;
		io-width = <0x20>;
		tRFC-min-tck = <0x11>;
		tRRD-min-tck = <0x02>;
		tRPab-min-tck = <0x02>;
		tRPpb-min-tck = <0x02>;
		tRCD-min-tck = <0x03>;
		tRC-min-tck = <0x06>;
		tRAS-min-tck = <0x05>;
		tWTR-min-tck = <0x02>;
		tWR-min-tck = <0x07>;
		tRTP-min-tck = <0x02>;
		tW2W-C2C-min-tck = <0x00>;
		tR2R-C2C-min-tck = <0x00>;
		tWL-min-tck = <0x08>;
		tDQSCK-min-tck = <0x05>;
		tRL-min-tck = <0x0e>;
		tFAW-min-tck = <0x05>;
		tXSR-min-tck = <0x0c>;
		tXP-min-tck = <0x02>;
		tCKE-min-tck = <0x02>;
		tCKESR-min-tck = <0x02>;
		tMRD-min-tck = <0x05>;
		phandle = <0x3d>;

		timings {
			compatible = "jedec,lpddr3-timings";
			max-freq = <0x2faf0800>;
			min-freq = <0x5f5e100>;
			tRFC = <0xfde8>;
			tRRD = <0x1770>;
			tRPab = <0x2ee0>;
			tRPpb = <0x2ee0>;
			tRCD = <0x2710>;
			tRC = <0x83d6>;
			tRAS = <0x59d8>;
			tWTR = <0xea6>;
			tWR = <0x1d4c>;
			tRTP = <0xea6>;
			tW2W-C2C = <0x00>;
			tR2R-C2C = <0x00>;
			tFAW = <0x61a8>;
			tXSR = <0x11170>;
			tXP = <0xea6>;
			tCKE = <0xea6>;
			tCKESR = <0xea6>;
			tMRD = <0x1b58>;
		};
	};

	gpio-keys {
		compatible = "gpio-keys";
		pinctrl-names = "default";
		pinctrl-0 = <0xa7>;

		power-key {
			gpios = <0x17 0x03 0x01>;
			linux,code = <0x74>;
			label = "power key";
			debounce-interval = <0x00>;
			wakeup-source;
		};
	};

	pwrseq {
		pinctrl-0 = <0xa8>;
		pinctrl-names = "default";
		compatible = "mmc-pwrseq-emmc";
		reset-gpios = <0xa9 0x00 0x01>;
		phandle = <0x27>;
	};

	pwm-fan {
		compatible = "pwm-fan";
		pwms = <0xaa 0x00 0x51ec 0x00>;
		#cooling-cells = <0x02>;
		cooling-levels = <0x00 0x82 0xaa 0xe6>;
		phandle = <0x84>;
	};

	led-controller {
		compatible = "pwm-leds";

		led-1 {
			function = "heartbeat";
			color = <0x03>;
			pwms = <0xaa 0x02 0x1e8480 0x00>;
			pwm-names = "pwm2";
			max-brightness = <0xff>;
			linux,default-trigger = "heartbeat";
		};
	};

	sound {
		compatible = "samsung,odroid-xu3-audio";
		model = "Odroid-XU4";
		audio-routing = "I2S Playback", "Mixer DAI TX";

		cpu {
			sound-dai = <0x43 0x00 0x43 0x01>;
		};

		codec {
			sound-dai = <0x53>;
		};
	};
};
